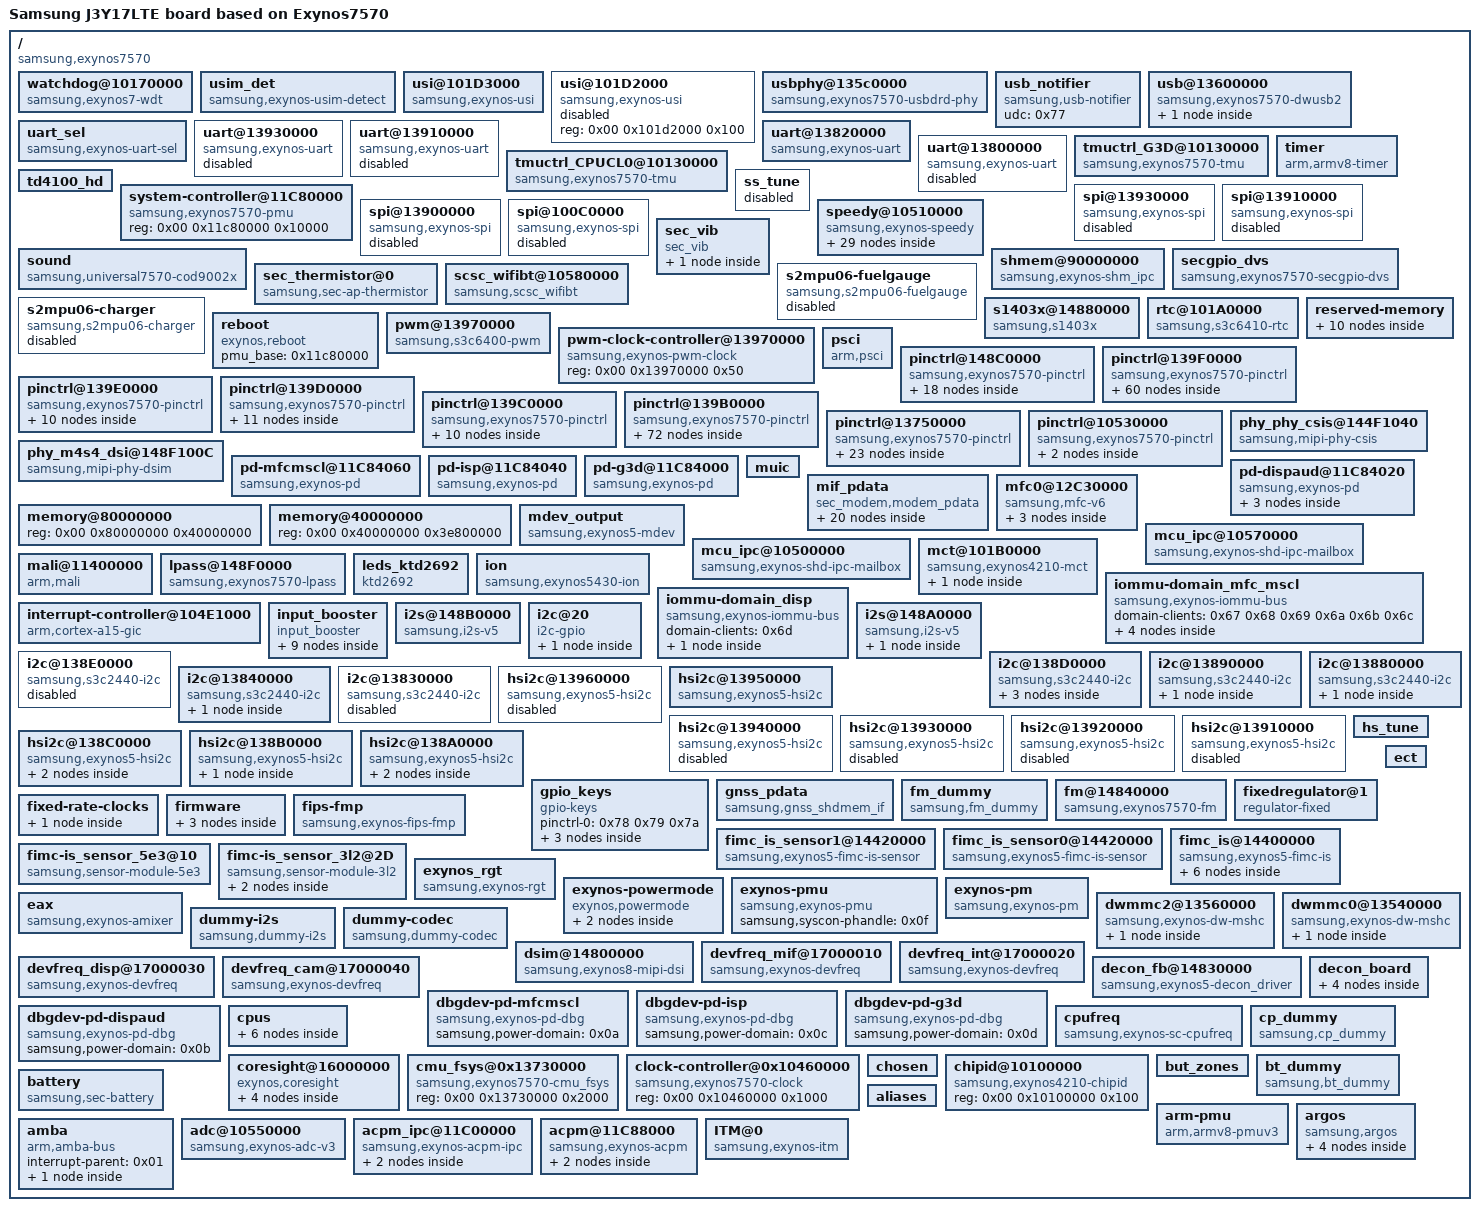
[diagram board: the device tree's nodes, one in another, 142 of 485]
/dts-v1/;

/ {
	#address-cells = <0x02>;
	#size-cells = <0x01>;
	compatible = "samsung,exynos7570\0samsung,exynos4210";
	interrupt-parent = <0x01>;
	model = "Samsung J3Y17LTE board based on Exynos7570";
	model_info-chip = <0x1d92>;
	model_info-hw_rev = <0x04>;
	model_info-hw_rev_end = <0xff>;
	model_info-platform = "android";
	model_info-subtype = "samsung";
	model_info-system_rev = "004";

	watchdog@10170000 {
		reg = <0x00 0x10170000 0x100>;
		interrupts = <0x00 0x64 0x00>;
		compatible = "samsung,exynos7-wdt";
		clock-names = "rate_watchdog\0gate_watchdog";
		timeout-sec = <0x1e>;
		clocks = <0x11 0x173 0x11 0x173>;
		samsung,syscon-phandle = <0x0f>;
	};

	usim_det {
		mif,usim-det0-gpio = <0x17 0x04 0x00>;
		pinctrl-0 = <0x15 0x16>;
		mif,usim-det1-gpio = <0x18 0x04 0x00>;
		compatible = "samsung,exynos-usim-detect";
		mif,int_usim1_det_level = <0x05>;
		mbx_ap2cp_united_status = <0x02>;
		sbi_usim1_det_pos = <0x12>;
		mif,int_usim0_det_level = <0x04>;
		sbi_usim0_det_mask = <0x01>;
		mif,num_of_usim_det = <0x02>;
		sbi_usim0_det_pos = <0x11>;
		sbi_usim1_det_mask = <0x01>;
		pinctrl-names = "default";
	};

	usi@101D3000 {
		reg = <0x00 0x101d3000 0x100>;
		compatible = "samsung,exynos-usi";
		status = "okay";
		usi_mode = "hsi2c1";
	};

	usi@101D2000 {
		reg = <0x00 0x101d2000 0x100>;
		compatible = "samsung,exynos-usi";
		status = "disabled";
	};

	usbphy@135c0000 {
		reg = <0x00 0x135c0000 0x100>;
		compatible = "samsung,exynos7570-usbdrd-phy";
		clock-names = "usbdrd20\0phyumux\0usb_pll";
		#phy-cells = <0x01>;
		use_additional_tuning;
		request_extrefclk;
		clocks = <0x11 0x200 0x11 0x208 0x11 0x212>;
		uart_io_share_mask = <0x01>;
		is_not_vbus_pad;
		ss_tune_info = <0x70>;
		status = "okay";
		samsung,pmu-syscon = <0x0f>;
		uart_io_share_enable = <0x01>;
		phandle = <0x6e>;
		uart_io_share_offset = <0x6200>;
		linux,phandle = <0x6e>;
		hs_tune_info = <0x6f>;
	};

	usb_notifier {
		udc = <0x77>;
		compatible = "samsung,usb-notifier";
	};

	usb@13600000 {
		reg = <0x00 0x13600000 0x10000>;
		compatible = "samsung,exynos7570-dwusb2";
		clock-names = "usbdrd20";
		clocks = <0x11 0x200>;
		ranges;
		status = "okay";
		#address-cells = <0x02>;
		phandle = <0x77>;
		#size-cells = <0x01>;
		linux,phandle = <0x77>;

		dwc3 {
			reg = <0x00 0x13600000 0x10000>;
			maximum-speed = "high-speed";
			phys = <0x6e 0x00 0x6e 0x01>;
			interrupts = <0x00 0xe6 0x00>;
			enable_sprs_transfer;
			compatible = "synopsys,dwc3";
			dr_mode = "otg";
			phy-names = "usb2-phy\0usb3-phy";
			is_not_vbus_pad;
			suspend_clk_freq = <0x3fe56c0>;
		};
	};

	uart_sel {
		int_ap2cp_uart_noti = <0x0f>;
		compatible = "samsung,exynos-uart-sel";
		mbx_ap2cp_united_status = <0x02>;
		sbi_uart_noti_pos = <0x10>;
		sbi_uart_noti_mask = <0x01>;
	};

	uart@13930000 {
		reg = <0x00 0x13930000 0x100>;
		interrupts = <0x00 0x1d1 0x00>;
		pinctrl-0 = <0x1a>;
		compatible = "samsung,exynos-uart";
		clock-names = "gate_pclk4\0gate_uart4\0sclk_uart4";
		clocks = <0x11 0x160 0x11 0x29 0x11 0x29>;
		samsung,fifo-size = <0x20>;
		samsung,separate-uart-clk;
		status = "disabled";
		pinctrl-names = "default";
	};

	uart@13910000 {
		reg = <0x00 0x13910000 0x100>;
		interrupts = <0x00 0x1cd 0x00>;
		pinctrl-0 = <0x19>;
		compatible = "samsung,exynos-uart";
		clock-names = "gate_pclk3\0gate_uart3\0sclk_uart3";
		clocks = <0x11 0x15f 0x11 0x28 0x11 0x28>;
		samsung,fifo-size = <0x20>;
		samsung,separate-uart-clk;
		status = "disabled";
		pinctrl-names = "default";
	};

	uart@13820000 {
		reg = <0x00 0x13820000 0x100>;
		interrupts = <0x00 0x1a7 0x00>;
		pinctrl-0 = <0x13>;
		pinctrl-1 = <0x14>;
		compatible = "samsung,exynos-uart";
		clock-names = "gate_pclk2\0gate_uart2\0sclk_uart2";
		clocks = <0x11 0x168 0x11 0x14 0x11 0x14>;
		samsung,fifo-size = <0x100>;
		samsung,separate-uart-clk;
		status = "okay";
		samsung,alive-io;
		pinctrl-names = "default\0uart_sleep";
	};

	uart@13800000 {
		reg = <0x00 0x13800000 0x100>;
		interrupts = <0x00 0x1a5 0x00>;
		pinctrl-0 = <0x12>;
		compatible = "samsung,exynos-uart";
		clock-names = "gate_pclk1\0gate_uart1\0sclk_uart1";
		clocks = <0x11 0x169 0x11 0x15 0x11 0x15>;
		samsung,fifo-size = <0x10>;
		samsung,separate-uart-clk;
		status = "disabled";
		pinctrl-names = "default";
	};

	tmuctrl_G3D@10130000 {
		reg = <0x00 0x10130000 0x200>;
		interrupts = <0x00 0x1b3 0x00>;
		compatible = "samsung,exynos7570-tmu";
		gpu_idx_num = <0x05>;
		default_ptat_cont = <0x01>;
		gpu_cooling_table = <0x00 0x00 0xcaa30 0x00 0x01 0xa2990 0x00 0x02 0x87028 0x00 0x03 0x65518 0x00 0x04 0xfffffffe>;
	};

	tmuctrl_CPUCL0@10130000 {
		reg = <0x00 0x10130000 0x200>;
		interrupts = <0x00 0x1b3 0x00>;
		compatible = "samsung,exynos7570-tmu";
		default_ptat_cont = <0x01>;
	};

	timer {
		interrupts = <0x01 0x0d 0xff01 0x01 0x0e 0xff01 0x01 0x0b 0xff01 0x01 0x0a 0xff01>;
		compatible = "arm,armv8-timer";
		clock-frequency = <0x18cba80>;
		use-clocksource-only;
	};

	td4100_hd {
		rev = <0x02>;
		resolution = <0x2d0 0x500>;
		mode = <0x00>;
		size = <0x3e 0x6e>;
		timing,pms = <0x02 0x70 0x01>;
		timing,refresh = <0x3c>;
		timing,dsi-escape-clk = <0x10>;
		timing,decon_h-porch = <0x50 0x2f1 0x01>;
		timing,decon_v-porch = <0x0a 0x0a 0x01>;
		timing,dsim_h-porch = <0x50 0x2ee 0x01>;
		timing,dsim_v-porch = <0x0a 0x0a 0x01>;
		dispif_resol = <0x2d0 0x500>;
		panel_name = "td4100";
		timing,dsi-hs-clk = <0x2d8>;
		phandle = <0x64>;
		linux,phandle = <0x64>;
	};

	system-controller@11C80000 {
		reg = <0x00 0x11c80000 0x10000>;
		compatible = "samsung,exynos7570-pmu\0syscon";
		phandle = <0x0f>;
		linux,phandle = <0x0f>;
	};

	ss_tune {
		enable_ssc = <0x01 0x01>;
		los_mask_val = <0x104 0x104>;
		ssc_range = <0x00 0x01>;
		tx_swing_low = <0x7f 0x7f>;
		tx_deemphasis_3p5db = <0x18 0x18>;
		tx_swing_full = <0x7f 0x7f>;
		fix_rxeq_value = <0x04 0x04>;
		tx_boost_level = <0x04 0x04>;
		status = "disabled";
		tx_swing_level = <0x01 0x01>;
		set_crport_mpll_charge_pump = <0x00 0x00>;
		tx_deemphasis_6db = <0x18 0x18>;
		phandle = <0x70>;
		enable_fixed_rxeq_mode = <0x00 0x00>;
		set_crport_level_en = <0x00 0x00>;
		los_bias = <0x05 0x05>;
		tx_deemphasis_mode = <0x01 0x01>;
		linux,phandle = <0x70>;
	};

	spi@13930000 {
		reg = <0x00 0x13930000 0x100>;
		interrupts = <0x00 0x1d2 0x00>;
		pinctrl-0 = <0x4d>;
		compatible = "samsung,exynos-spi";
		clock-names = "spi\0spi_busclk0";
		clocks = <0x11 0x160 0x11 0x29>;
		swap-mode;
		samsung,spi-fifosize = <0x20>;
		status = "disabled";
		#address-cells = <0x01>;
		#size-cells = <0x00>;
		dma-names = "tx\0rx";
		pinctrl-names = "default";
	};

	spi@13910000 {
		reg = <0x00 0x13910000 0x100>;
		interrupts = <0x00 0x1ce 0x00>;
		pinctrl-0 = <0x4c>;
		compatible = "samsung,exynos-spi";
		clock-names = "spi\0spi_busclk0";
		clocks = <0x11 0x15f 0x11 0x28>;
		swap-mode;
		samsung,spi-fifosize = <0x20>;
		status = "disabled";
		#address-cells = <0x01>;
		#size-cells = <0x00>;
		dma-names = "tx\0rx";
		pinctrl-names = "default";
	};

	spi@13900000 {
		reg = <0x00 0x13900000 0x100>;
		interrupts = <0x00 0x1b1 0x00>;
		pinctrl-0 = <0x4b>;
		compatible = "samsung,exynos-spi";
		clock-names = "spi\0spi_busclk0";
		clocks = <0x11 0x16b 0x11 0x16>;
		swap-mode;
		samsung,spi-fifosize = <0x40>;
		status = "disabled";
		#address-cells = <0x01>;
		#size-cells = <0x00>;
		dma-names = "tx\0rx";
		pinctrl-names = "default";
	};

	spi@100C0000 {
		reg = <0x00 0x100c0000 0x100>;
		interrupts = <0x00 0x1b2 0x00>;
		pinctrl-0 = <0x4a>;
		compatible = "samsung,exynos-spi";
		clock-names = "spi\0spi_busclk0";
		clocks = <0x11 0x16a 0x11 0x17>;
		swap-mode;
		samsung,spi-fifosize = <0x100>;
		status = "disabled";
		#address-cells = <0x01>;
		#size-cells = <0x00>;
		dma-names = "tx\0rx";
		pinctrl-names = "default";
	};

	speedy@10510000 {
		reg = <0x00 0x10510000 0x2000>;
		samsung,always-interrupt-high;
		interrupts = <0x00 0x174 0x00>;
		pinctrl-0 = <0x43>;
		compatible = "samsung,exynos-speedy";
		clock-names = "gate_speedy";
		clocks = <0x11 0x0b>;
		status = "okay";
		#address-cells = <0x01>;
		#size-cells = <0x00>;
		pinctrl-names = "default";

		cod9002x@03 {
			reg = <0x03>;
			i2c-speedy-address;
			mic-bias2-voltage = <0x01>;
			compatible = "codec,cod9002x";
			but-zones-list = <0x46 0xe2 0x00 0xd9 0x46 0x246 0xda 0x128 0x46 0x73 0x129 0x1f2 0x46 0x72 0x1f3 0x3e8>;
			io-channel-names = "adc-jack";
			use-jack-pullup-mode;
			io-channel-ranges;
			mic-bias1-voltage = <0x01>;
			use-btn-adc-mode;
			io-channels = <0x45 0x02>;
			mic-adc-range = <0x546>;
			phandle = <0x49>;
			vdd-supply = <0x44>;
			mic-bias-ldo-voltage = <0x03>;
			btn-press-delay = <0x00>;
			#io-channel-cells = <0x01>;
			pinctrl-names = "default";
			linux,phandle = <0x49>;
		};

		s2mpu06mfd@00 {
			reg = <0x00>;
			samsung,codec-interrupt = <0x49>;
			wtsr_en = "enabled";
			i2c-speedy-address;
			pinctrl-0 = <0x47>;
			cache_data = <0x01>;
			s2mpu06,irq-gpio = <0x48 0x05 0x00>;
			check_jigon = <0x00>;
			compatible = "samsung,s2mpu06mfd";
			smpl_timer_val = <0x00>;
			smpl_en = "enabled";
			wtsr_timer_val = <0x03>;
			s2mpu06,wakeup = "enabled";
			init_time,hour = <0x0c>;
			init_time,mday = <0x01>;
			init_time,wday = <0x00>;
			init_time,year = <0x75>;
			pinctrl-names = "default";
			init_time,min = <0x00>;
			init_time,mon = <0x00>;
			init_time,sec = <0x00>;

			s2mpu06-keys {

				button@1 {
					label = "pmic-keys: KEY_POWER";
					linux,code = <0x74>;
					wakeup = <0x01>;
				};
			};

			regulators {

				LDO24 {
					regulator-name = "AVDD24_CAM_2P8";
					regulator-min-microvolt = <0x2ab980>;
					regulator-max-microvolt = <0x2ab980>;
					regulator-initial-mode = <0x00>;
					regulator-ramp-delay = <0x2ee0>;
				};

				LDO23 {
					regulator-name = "VDD23_CAM_CORE_1P2";
					regulator-min-microvolt = <0x124f80>;
					regulator-max-microvolt = <0x124f80>;
					regulator-initial-mode = <0x00>;
					regulator-ramp-delay = <0x2ee0>;
				};

				LDO22 {
					regulator-name = "vdd_ldo22";
					regulator-always-on;
					regulator-min-microvolt = <0x1b7740>;
					regulator-max-microvolt = <0x337f98>;
					regulator-initial-mode = <0x03>;
					phandle = <0x28>;
					regulator-ramp-delay = <0x2ee0>;
					linux,phandle = <0x28>;
				};

				LDO21 {
					regulator-name = "vdd_ldo21";
					regulator-min-microvolt = <0x1b7740>;
					regulator-max-microvolt = <0x337f98>;
					regulator-initial-mode = <0x00>;
					regulator-ramp-delay = <0x2ee0>;
				};

				LDO20 {
					regulator-name = "LCD_1P8";
					regulator-min-microvolt = <0x1b7740>;
					regulator-max-microvolt = <0x1b7740>;
					regulator-initial-mode = <0x03>;
					regulator-boot-on;
				};

				LDO19 {
					regulator-name = "vtouch_2.2v";
					regulator-min-microvolt = <0x2191c0>;
					regulator-max-microvolt = <0x2191c0>;
					regulator-boot-on;
				};

				LDO18 {
					regulator-name = "VDD28_CAM_AF";
					regulator-min-microvolt = <0x2ab980>;
					regulator-max-microvolt = <0x2ab980>;
					regulator-initial-mode = <0x00>;
					regulator-ramp-delay = <0x2ee0>;
				};

				LDO17 {
					regulator-name = "VDD18_CAM_SENSOR_IO";
					regulator-min-microvolt = <0x1b7740>;
					regulator-max-microvolt = <0x1b7740>;
					regulator-initial-mode = <0x00>;
					regulator-ramp-delay = <0x2ee0>;
				};

				LDO16 {
					regulator-name = "VDD_MOTOR_3P3";
					regulator-min-microvolt = <0x325aa0>;
					regulator-max-microvolt = <0x325aa0>;
					regulator-initial-mode = <0x00>;
					regulator-ramp-delay = <0x2ee0>;
				};

				LDO15 {
					regulator-name = "vqemmc";
					regulator-min-microvolt = "\0\f5";
					regulator-max-microvolt = <0x1e8480>;
					regulator-initial-mode = <0x00>;
					regulator-ramp-delay = <0x2ee0>;
				};

				LDO14 {
					regulator-name = "vemmc";
					regulator-min-microvolt = <0x1b7740>;
					regulator-max-microvolt = <0x337f98>;
					regulator-initial-mode = <0x00>;
					regulator-ramp-delay = <0x2ee0>;
				};

				LDO13 {
					regulator-name = "vdd_ldo13";
					regulator-always-on;
					regulator-min-microvolt = "\0\f5";
					regulator-max-microvolt = <0x1e8480>;
					regulator-initial-mode = <0x03>;
					phandle = <0x44>;
					regulator-boot-on;
					regulator-ramp-delay = <0x2ee0>;
					linux,phandle = <0x44>;
				};

				BUCK3 {
					regulator-name = "BUCK3";
					regulator-always-on;
					regulator-min-microvolt = "\0\f5";
					regulator-max-microvolt = <0x2ab980>;
					regulator-initial-mode = <0x03>;
					regulator-boot-on;
					regulator-ramp-delay = <0x2ee0>;
				};

				BUCK2 {
					regulator-name = "BUCK2";
					regulator-always-on;
					regulator-min-microvolt = "\0\f5";
					regulator-max-microvolt = <0x2ab980>;
					regulator-initial-mode = <0x03>;
					regulator-boot-on;
					regulator-ramp-delay = <0x2ee0>;
				};

				BUCK1 {
					regulator-expected-consumer = <0x06>;
					regulator-name = "BUCK1";
					regulator-always-on;
					regulator-min-microvolt = <0x7a120>;
					regulator-max-microvolt = <0x13d620>;
					regulator-initial-mode = <0x01>;
					regulator-boot-on;
					regulator-ramp-delay = <0x2ee0>;
				};

				LDO8 {
					regulator-name = "vdd_ldo8";
					regulator-always-on;
					regulator-min-microvolt = <0x1b7740>;
					regulator-max-microvolt = <0x337f98>;
					regulator-initial-mode = <0x01>;
					regulator-boot-on;
					regulator-ramp-delay = <0x2ee0>;
				};

				LDO7 {
					regulator-name = "vdd_ldo7";
					regulator-always-on;
					regulator-min-microvolt = "\0\f5";
					regulator-max-microvolt = <0x13d620>;
					regulator-initial-mode = <0x01>;
					regulator-boot-on;
					regulator-ramp-delay = <0x2ee0>;
				};

				LDO6 {
					regulator-name = "vdd_ldo6";
					regulator-always-on;
					regulator-min-microvolt = <0x7a120>;
					regulator-max-microvolt = <0x13d620>;
					regulator-initial-mode = <0x03>;
					regulator-boot-on;
					regulator-ramp-delay = <0x2ee0>;
				};

				LDO5 {
					regulator-name = "vdd_ldo5";
					regulator-always-on;
					regulator-min-microvolt = <0x19f0a0>;
					regulator-max-microvolt = <0x331df0>;
					regulator-initial-mode = <0x03>;
					regulator-boot-on;
					regulator-ramp-delay = <0x2ee0>;
				};

				LDO4 {
					regulator-name = "vqmmc";
					regulator-min-microvolt = <0x19f0a0>;
					regulator-max-microvolt = <0x331df0>;
					regulator-initial-mode = <0x00>;
					regulator-ramp-delay = <0x2ee0>;
				};

				LDO3 {
					regulator-name = "vdd_ldo3";
					regulator-always-on;
					regulator-min-microvolt = "\0\f5";
					regulator-max-microvolt = <0x16e360>;
					regulator-initial-mode = <0x03>;
					regulator-boot-on;
					regulator-ramp-delay = <0x2ee0>;
				};

				LDO2 {
					regulator-name = "vdd_ldo2";
					regulator-always-on;
					regulator-min-microvolt = <0x16e360>;
					regulator-max-microvolt = <0x1e8480>;
					regulator-initial-mode = <0x03>;
					phandle = <0x26>;
					regulator-boot-on;
					regulator-ramp-delay = <0x2ee0>;
					linux,phandle = <0x26>;
				};

				LDO1 {
					regulator-name = "vdd_ldo1";
					regulator-always-on;
					regulator-min-microvolt = <0x7a120>;
					regulator-max-microvolt = <0x13d620>;
					regulator-initial-mode = <0x01>;
					regulator-boot-on;
					regulator-ramp-delay = <0x2ee0>;
				};
			};
		};

		fimc_is_flash@06 {
			id = <0x00>;
			reg = <0x06>;
			i2c-speedy-address;
			torch_level1 = <0x00>;
			torch_level2 = <0x01>;
			torch_level3 = <0x02>;
			torch_level4 = <0x03>;
			torch_level5 = <0x06>;
			compatible = "samsung,sensor-flash-i2c";
			flash-gpio = <0x48 0x00 0x00>;
			flash_current = <0x4b0>;
			factory_current = <0xa0>;
			torch_current = <0x50>;
			movie_current = <0xa0>;
			preflash_current = <0xa0>;
		};
	};

	sound {
		compatible = "samsung,universal7570-cod9002x";
		status = "okay";
		samsung,audio-cpu = <0x84 0x84 0x85 0x86 0x87 0x88 0x85 0x89 0x89 0x89 0x89>;
		samsung,audio-codec = <0x49 0x49 0x49 0x8a 0x49 0x8a 0x8a 0x49 0x49 0x49 0x49>;
		mic-bias-mode = <0x01 0x01 0x02 0x00>;
		samsung,auxdev = <0x8b>;
	};

	shmem@90000000 {
		compatible = "samsung,exynos-shm_ipc";
		shmem,ipc_size = <0x400000>;
		shmem,ipc_offset = <0x5800000>;
	};

	secgpio_dvs {
		compatible = "samsung,exynos7570-secgpio-dvs";
		status = "okay";
	};

	sec_vib {
		compatible = "sec_vib";

		sec_vib_pdata {
			sec_vib,regulator = "VDD_MOTOR_3P3";
			sec_vib,max_timeout = <0x2710>;
			status = "okay";
			sec_vib,ldo_type = <0x00>;
		};
	};

	sec_thermistor@0 {
		compatible = "samsung,sec-ap-thermistor";
		io-channel-names = "adc-ap-temp";
		io-channel-ranges;
		status = "okay";
		io-channels = <0x45 0x00>;
		temp_array = <0x384 0x37a 0x370 0x366 0x35c 0x352 0x348 0x33e 0x334 0x32a 0x320 0x316 0x30c 0x302 0x2f8 0x2ee 0x2e4 0x2da 0x2d0 0x2c6 0x2bc 0x2b2 0x2a8 0x29e 0x294 0x28a 0x280 0x276 0x26c 0x262 0x258 0x24e 0x244 0x23a 0x230 0x226 0x21c 0x212 0x208 0x1fe 0x1f4 0x1ea 0x1e0 0x1d6 0x1cc 0x1c2 0x1b8 0x1ae 0x1a4 0x19a 0x190 0x186 0x17c 0x172 0x168 0x15e 0x154 0x14a 0x140 0x136 0x12c 0x122 0x118 0x10e 0x104 0xfa 0xf0 0xe6 0xdc 0xd2 0xc8 0xbe 0xb4 0xaa 0xa0 0x96 0x8c 0x82 0x78 0x6e 0x64 0x5a 0x50 0x46 0x3c 0x32 0x28 0x1e 0x14 0x0a 0x00 0xfffffff6 0xffffffec 0xffffffe2 0xffffffd8 0xffffffce 0xffffffc4 0xffffffba 0xffffffb0 0xffffffa6 0xffffff9c 0xffffff92 0xffffff88 0xffffff7e 0xffffff74 0xffffff6a 0xffffff60 0xffffff56 0xffffff4c 0xffffff42 0xffffff38>;
		adc_array = <0x11d 0x128 0x132 0x13d 0x147 0x152 0x15e 0x169 0x175 0x180 0x18c 0x198 0x1a4 0x1b1 0x1bd 0x1c9 0x1da 0x1eb 0x1fc 0x20d 0x21d 0x233 0x248 0x25d 0x272 0x288 0x29c 0x2b2 0x2c7 0x2dc 0x2f1 0x308 0x31e 0x336 0x34c 0x364 0x382 0x3a0 0x3be 0x3dc 0x3fa 0x41b 0x43c 0x45d 0x47e 0x49f 0x4c1 0x4e3 0x506 0x528 0x54a 0x573 0x59b 0x5c4 0x5ec 0x615 0x643 0x671 0x6a0 0x6cf 0x6fd 0x727 0x752 0x77d 0x7a7 0x7d1 0x801 0x831 0x861 0x892 0x8c2 0x8f3 0x924 0x955 0x985 0x9b5 0x9e3 0xa10 0xa3e 0xa6b 0xa99 0xac3 0xaed 0xb16 0xb40 0xb6a 0xb95 0xbbf 0xbea 0xc14 0xc3f 0xc60 0xc81 0xca3 0xcc4 0xce5 0xd02 0xd20 0xd3d 0xd5b 0xd78 0xd8e 0xda4 0xdba 0xdd0 0xde6 0xdfe 0xe17 0xe2f 0xe48 0xe60>;
	};

	scsc_wifibt@10580000 {
		reg = <0x00 0x10580000 0x180>;
		interrupts = <0x00 0x178 0x04 0x00 0x15 0x04 0x00 0x1dc 0x04>;
		compatible = "samsung,scsc_wifibt";
		interrupt-names = "MBOX\0ALIVE\0WDOG";
		samsung,syscon-cmu_fsys = <0x66>;
		usbpll,udelay = <0x14>;
		status = "okay";
		samsung,syscon-phandle = <0x0f>;
		usbpll,owner = "y";
	};

	s2mpu06-fuelgauge {
		fuelgauge,capacity_full = <0x960>;
		fuelgauge,fuel_alert_soc = <0x01>;
		fuelgauge,model_type = <0x01>;
		fuelgauge,capacity_max = <0x3e8>;
		fuelgauge,capacity_min = <0x00>;
		compatible = "samsung,s2mpu06-fuelgauge";
		fuelgauge,capacity_max_margin = <0x46>;
		fuelgauge,raw_100_vbat = <0x10d1 0x10cc 0x10b9 0x10a5 0x1077>;
		status = "disable";
		fuelgauge,capacity_calculation_type = <0x1c>;
		fuelgauge,cell_character = <0xb8 0x0a 0x71 0x0a 0xe2 0x09 0x74 0x09 0x21 0x09 0x83 0x08 0x25 0x08 0xd6 0x07 0x8d 0x07 0x3e 0x07 0xe0 0x06 0xaa 0x06 0x82 0x06 0x63 0x06 0x4a 0x06 0x33 0x06 0x0f 0x06 0xe8 0x05 0xaf 0x05 0x85 0x05 0x22 0x05 0x35 0x02 0x69 0x08 0x00 0x08 0x97 0x07 0x2e 0x07 0xc5 0x06 0x5c 0x06 0xf3 0x05 0x8b 0x05 0x22 0x05 0xb9 0x04 0x50 0x04 0xe7 0x03 0x7e 0x03 0x15 0x03 0xac 0x02 0x43 0x02 0xda 0x01 0x72 0x01 0x09 0x01 0xa0 0x00 0x37 0x00 0xe0 0x0f 0xfe 0x29 0xdc 0x29 0x8a 0x29 0x4d 0x29 0x28 0x1f 0x7f 0x1f 0x21 0x21 0x14 0x21 0xe8 0x0f 0xe6 0xf7 0xc4 0x1d 0xca 0xd4 0xd3 0xd4 0x40 0x80 0x26 0x33 0x26 0x40 0x26 0x5c 0x26 0x5c 0x26 0x5c 0xff 0xff 0x02 0x05 0x14 0x0b 0x03 0x12 0x06 0x1c 0x0c 0x1c 0x10 0x1c 0x1f 0x1f 0x30 0x30 0x38 0x38 0x38 0x38 0x38 0x38 0x3d 0x3d 0x3e 0x3f 0x3f 0x3f 0x40 0x4b 0x4b 0x4c 0x4e 0x4d 0x71 0xa4 0x05 0x60 0x09 0x00 0x00 0x66 0x0a 0xf5 0x09 0x8a 0x09 0x22 0x09 0xc1 0x08 0x6d 0x08 0x00 0x08 0xbe 0x07 0x67 0x07 0x05 0x07 0xc9 0x06 0x9d 0x06 0x79 0x06 0x5c 0x06 0x43 0x06 0x26 0x06 0x04 0x06 0xdc 0x05 0xa8 0x05 0x84 0x05 0xd6 0x04 0x7f 0x01 0x00 0x08 0xa0 0x07 0x3d 0x07 0xda 0x06 0x78 0x06 0x15 0x06 0xb2 0x05 0x4f 0x05 0xec 0x04 0x8a 0x04 0x27 0x04 0xc4 0x03 0x61 0x03 0xfe 0x02 0x9c 0x02 0x39 0x02 0xd6 0x01 0x73 0x01 0x10 0x01 0xae 0x00 0x4b 0x00 0xe8 0x0f 0xfe 0x29 0xdc 0x29 0x8a 0x29 0x4d 0x29 0x28 0x1f 0x7f 0x1f 0x21 0x21 0x14 0x21 0xf7 0x0f 0xe6 0xf7 0xc4 0x1d 0xca 0xd4 0xd3 0xd4 0x40 0x80 0x26 0x33 0x26 0x40 0x26 0x5c 0x26 0x5c 0x26 0x5c 0xff 0xff 0x02 0x05 0x14 0x0b 0x03 0x12 0x06 0x1c 0x0c 0x1c 0x10 0x1c 0x1f 0x1f 0x37 0x37 0x37 0x37 0x37 0x38 0x38 0x37 0x37 0x38 0x38 0x38 0x38 0x39 0x39 0x39 0x39 0x39 0x3a 0x3b 0x41 0xc8 0x05 0x60 0x09 0x00 0x00 0x40 0x0a 0xd2 0x09 0x69 0x09 0x04 0x09 0xa5 0x08 0x4f 0x08 0xee 0x07 0xab 0x07 0x53 0x07 0xf7 0x06 0xc0 0x06 0x96 0x06 0x74 0x06 0x59 0x06 0x41 0x06 0x23 0x06 0x01 0x06 0xda 0x05 0xa5 0x05 0x86 0x05 0xe4 0x04 0x7c 0x01 0x00 0x08 0xa1 0x07 0x3e 0x07 0xdb 0x06 0x78 0x06 0x15 0x06 0xb2 0x05 0x4f 0x05 0xed 0x04 0x8a 0x04 0x27 0x04 0xc4 0x03 0x61 0x03 0xfe 0x02 0x9c 0x02 0x39 0x02 0xd6 0x01 0x73 0x01 0x10 0x01 0xad 0x00 0x4b 0x00 0xe8 0x0f 0xfe 0x29 0xdc 0x29 0x8a 0x29 0x4d 0x29 0x28 0x1f 0x7f 0x1f 0x21 0x21 0x14 0x21 0xf7 0x0f 0xe6 0xf7 0xc4 0x1d 0xca 0xd4 0xd3 0xd4 0x40 0x80 0x26 0x33 0x26 0x40 0x26 0x5c 0x26 0x5c 0x26 0x5c 0xff 0xff 0x02 0x05 0x14 0x0b 0x03 0x12 0x06 0x1c 0x0c 0x1c 0x10 0x1c 0x1f 0x1f 0x36 0x36 0x36 0x37 0x36 0x38 0x38 0x37 0x37 0x37 0x38 0x38 0x38 0x38 0x39 0x39 0x38 0x39 0x3a 0x3b 0x40 0xcd 0x05 0x60 0x09 0x00 0x00 0x17 0x0a 0xa8 0x09 0x41 0x09 0xdf 0x08 0x8a 0x08 0x1d 0x08 0xdb 0x07 0x95 0x07 0x33 0x07 0xe3 0x06 0xb2 0x06 0x8b 0x06 0x6b 0x06 0x52 0x06 0x3d 0x06 0x1f 0x06 0xfc 0x05 0xd7 0x05 0xa0 0x05 0x85 0x05 0x0b 0x05 0x7e 0x01 0x00 0x08 0x9d 0x07 0x3a 0x07 0xd7 0x06 0x74 0x06 0x11 0x06 0xae 0x05 0x4b 0x05 0xe7 0x04 0x84 0x04 0x21 0x04 0xbe 0x03 0x5b 0x03 0xf8 0x02 0x95 0x02 0x32 0x02 0xcf 0x01 0x6c 0x01 0x09 0x01 0xa6 0x00 0x43 0x00 0xe5 0x0f 0xfe 0x29 0xdc 0x29 0x8a 0x29 0x4d 0x29 0x28 0x1f 0x7f 0x1f 0x21 0x21 0x14 0x21 0xf7 0x0f 0xe6 0xf7 0xc4 0x1d 0xca 0xd4 0xd3 0xd4 0x40 0x80 0x26 0x33 0x26 0x40 0x26 0x5c 0x26 0x5c 0x26 0x5c 0xff 0xff 0x02 0x05 0x14 0x0b 0x03 0x12 0x06 0x1c 0x0c 0x1c 0x10 0x1c 0x1f 0x1f 0x35 0x36 0x36 0x36 0x36 0x36 0x38 0x37 0x37 0x37 0x37 0x37 0x38 0x38 0x39 0x39 0x39 0x39 0x3a 0x3b 0x3f 0xd0 0x05 0x60 0x09 0x00 0x00 0xb7 0x09 0x4f 0x09 0xee 0x08 0x95 0x08 0x34 0x08 0xe8 0x07 0xa7 0x07 0x51 0x07 0xf4 0x06 0xbf 0x06 0x97 0x06 0x76 0x06 0x5b 0x06 0x45 0x06 0x2b 0x06 0x08 0x06 0xea 0x05 0xbb 0x05 0x89 0x05 0x7a 0x05 0x08 0x04 0x64 0x01 0x00 0x08 0x9b 0x07 0x36 0x07 0xd0 0x06 0x6b 0x06 0x06 0x06 0xa1 0x05 0x3c 0x05 0xd7 0x04 0x72 0x04 0x0c 0x04 0xa7 0x03 0x42 0x03 0xdd 0x02 0x78 0x02 0x13 0x02 0xae 0x01 0x49 0x01 0xe4 0x00 0x7e 0x00 0x19 0x00 0xe7 0x0f 0xfe 0x29 0xdc 0x29 0x8a 0x29 0x4d 0x29 0x28 0x1f 0x7f 0x1f 0x21 0x21 0x14 0x21 0xf7 0x0f 0xe6 0xf7 0xc4 0x1d 0xca 0xd4 0xd3 0xd4 0x40 0x80 0x26 0x33 0x26 0x40 0x26 0x5c 0x26 0x5c 0x26 0x5c 0xff 0xff 0x02 0x05 0x14 0x0b 0x03 0x12 0x06 0x1c 0x0c 0x1c 0x10 0x1c 0x1f 0x1f 0x35 0x36 0x36 0x37 0x37 0x39 0x38 0x38 0x37 0x38 0x38 0x38 0x38 0x39 0x38 0x38 0x38 0x39 0x39 0x3b 0x43 0xc1 0x05 0x60 0x09 0x00 0x00>;
		fuelgauge,type_str = "SDI";
	};

	s2mpu06-charger {
		battery,chg_gpio_status = <0x00>;
		compatible = "samsung,s2mpu06-charger";
		battery,chg_polarity_en = <0x00>;
		battery,chg_gpio_en = <0x00>;
		battery,chg_polarity_status = <0x00>;
		status = "disable";
		battery,is_1MHz_switching = <0x01>;
	};

	s1403x@14880000 {
		reg = <0x00 0x14880000 0x200>;
		pinctrl-0 = <0x3b 0x3c>;
		pinctrl-1 = <0x3d>;
		compatible = "samsung,s1403x";
		clock-names = "audmixer_dout\0audmixer_aclk";
		clocks = <0x11 0x2e6 0x11 0x2c6>;
		samsung,lpass-subip;
		status = "okay";
		phandle = <0x8b>;
		pinctrl-names = "default\0idle";
		linux,phandle = <0x8b>;
	};

	rtc@101A0000 {
		reg = <0x00 0x101a0000 0x100>;
		interrupts = <0x00 0x5c 0x00 0x00 0x5d 0x00>;
		compatible = "samsung,s3c6410-rtc";
		clock-names = "gate_rtc";
		clocks = <0x11 0x176>;
	};

	reserved-memory {
		ranges;
		#address-cells = <0x02>;
		#size-cells = <0x01>;

		wifibt_if {
			reg = <0x00 0x79000000 0x400000>;
			compatible = "exynos,wifibt_if";
		};

		tima_region@0x52800000 {
			reg = <0x00 0x52800000 0x200000>;
			compatible = "removed-dma-pool";
		};

		video_stream {
			id = <0x03>;
			reg = <0x00 0x72200000 0x1200000>;
			compatible = "exynos8890-ion,vstream";
			compat-id = <0x19 0x1f>;
			secure;
		};

		video_scaler {
			id = <0x06>;
			reg = <0x00 0x71200000 0x1000000>;
			reusable;
			compatible = "exynos8890-ion,vscaler";
			compat-id = <0x1c>;
			secure;
		};

		gnss_if {
			reg = <0x00 0x7e100000 0x200000>;
			compatible = "exynos,gnss_if";
		};

		video_frame {
			id = <0x05>;
			reg = <0x00 0x79c00000 0x3800000>;
			ion,bulk_reclaim;
			reusable;
			compatible = "exynos8890-ion,vframe";
			compat-id = <0x1a 0x1d>;
			secure;
		};

		crypto {
			id = <0x01>;
			reg = <0x00 0x79400000 0x800000>;
			reusable;
			compatible = "exynos8890-ion,crypto";
		};

		camera {
			id = <0x0a>;
			reg = <0x00 0x710ef000 0x1000>;
			compatible = "exynos8890-ion,camera";
		};

		modem_if {
			reg = <0x00 0x73400000 0x5c00000>;
			compatible = "exynos,modem_if";
		};

		video_nfw {
			reg = <0x00 0x710f0000 0x110000>;
			fixed_lower_base = <0x40000000>;
			compatible = "exynos7570-mfc,vnfw";
			fixed_upper_base = <0xffffff80>;
		};
	};

	reboot {
		pmu_base = <0x11c80000>;
		compatible = "exynos,reboot";
	};

	pwm@13970000 {
		reg = <0x00 0x13970000 0x1000>;
		samsung,pwm-outputs = <0x00 0x01 0x02 0x03 0x04>;
		compatible = "samsung,s3c6400-pwm";
		clock-names = "gate_timers\0sclk_pwm\0pwm-scaler0\0pwm-scaler1\0pwm-tdiv0\0pwm-tdiv1\0pwm-tdiv2\0pwm-tdiv3\0pwm-tin0\0pwm-tin1\0pwm-tin2\0pwm-tin3";
		clocks = <0x11 0x14a 0x11 0x14b 0x71 0x01 0x71 0x02 0x71 0x05 0x71 0x06 0x71 0x07 0x71 0x08 0x71 0x0a 0x71 0x0b 0x71 0x0c 0x71 0x0d>;
		#pwm-cells = <0x03>;
		samsung,pwm-sclk-ctrl;
		status = "ok";
	};

	pwm-clock-controller@13970000 {
		reg = <0x00 0x13970000 0x50>;
		#clock-cells = <0x01>;
		compatible = "samsung,exynos-pwm-clock";
		phandle = <0x71>;
		linux,phandle = <0x71>;
	};

	psci {
		cpu_off = <0x84000002>;
		compatible = "arm,psci";
		cpu_suspend = <0xc4000001>;
		cpu_on = <0xc4000003>;
		method = "smc";
	};

	pinctrl@148C0000 {
		reg = <0x00 0x148c0000 0x1000>;
		interrupts = <0x00 0x44 0x00>;
		pinctrl-0 = <0x04>;
		compatible = "samsung,exynos7570-pinctrl";
		pinctrl-names = "sleep";

		i2s-pmic-bus {
			samsung,pin-function = <0x02>;
			samsung,pins = "gpz1-0\0gpz1-1\0gpz1-2\0gpz1-3";
			samsung,pin-drv = <0x00>;
			samsung,pin-pud = <0x01>;
		};

		fm-speedy-bus-idle {
			samsung,pin-function = <0x00>;
			samsung,pins = "gpz1-6";
			samsung,pin-drv = <0x02>;
			samsung,pin-pud = <0x03>;
		};

		i2s-amp-bus-idle {
			samsung,pin-function = <0x00>;
			samsung,pins = "gpz1-5";
			samsung,pin-drv = <0x02>;
			samsung,pin-pud = <0x03>;
		};

		i2s-pmic-amp-bus-idle {
			samsung,pin-function = <0x00>;
			samsung,pins = "gpz1-0\0gpz1-1\0gpz1-2\0gpz1-3\0gpz1-4\0gpz1-5";
			samsung,pin-drv = <0x00>;
			samsung,pin-pud = <0x01>;
			phandle = <0x3d>;
			linux,phandle = <0x3d>;
		};

		i2s-codec-clk {
			samsung,pin-function = <0x02>;
			samsung,pins = "gpz1-4";
			samsung,pin-drv = <0x00>;
			samsung,pin-pud = <0x01>;
			phandle = <0x3c>;
			linux,phandle = <0x3c>;
		};

		fm-speedy-bus {
			samsung,pin-function = <0x02>;
			samsung,pins = "gpz1-6";
			samsung,pin-drv = <0x02>;
			samsung,pin-pud = <0x03>;
		};

		i2s-pmic-amp-bus {
			samsung,pin-function = <0x02>;
			samsung,pins = "gpz1-0\0gpz1-1\0gpz1-2\0gpz1-3\0gpz1-4\0gpz1-5";
			samsung,pin-drv = <0x00>;
			samsung,pin-pud = <0x01>;
			phandle = <0x3b>;
			linux,phandle = <0x3b>;
		};

		i2s-pmic-bus-idle {
			samsung,pin-function = <0x00>;
			samsung,pins = "gpz1-0\0gpz1-1\0gpz1-2\0gpz1-3";
			samsung,pin-drv = <0x00>;
			samsung,pin-pud = <0x01>;
		};

		sleep-state {
			phandle = <0x04>;
			linux,phandle = <0x04>;

			gpz1-6 {
				samsung,pin-pud-pdn = <0x01>;
				samsung,pin-con-pdn = <0x02>;
				samsung,pins = "gpz1-6";
			};

			gpz1-5 {
				samsung,pin-pud-pdn = <0x01>;
				samsung,pin-con-pdn = <0x02>;
				samsung,pins = "gpz1-5";
			};

			gpz1-4 {
				samsung,pin-pud-pdn = <0x01>;
				samsung,pin-con-pdn = <0x02>;
				samsung,pins = "gpz1-4";
			};

			gpz1-3 {
				samsung,pin-pud-pdn = <0x01>;
				samsung,pin-con-pdn = <0x02>;
				samsung,pins = "gpz1-3";
			};

			gpz1-2 {
				samsung,pin-pud-pdn = <0x01>;
				samsung,pin-con-pdn = <0x02>;
				samsung,pins = "gpz1-2";
			};

			gpz1-1 {
				samsung,pin-pud-pdn = <0x01>;
				samsung,pin-con-pdn = <0x02>;
				samsung,pins = "gpz1-1";
			};

			gpz1-0 {
				samsung,pin-pud-pdn = <0x01>;
				samsung,pin-con-pdn = <0x02>;
				samsung,pins = "gpz1-0";
			};
		};

		i2s-amp-bus {
			samsung,pin-function = <0x02>;
			samsung,pins = "gpz1-5";
			samsung,pin-drv = <0x02>;
			samsung,pin-pud = <0x03>;
		};

		gpz1 {
			#gpio-cells = <0x02>;
			#interrupt-cells = <0x02>;
			interrupt-controller;
			gpio-controller;
		};
	};

	pinctrl@139F0000 {
		reg = <0x00 0x139f0000 0x1000>;
		interrupts = <0x00 0x00 0x00 0x00 0x01 0x00 0x00 0x02 0x00 0x00 0x03 0x00 0x00 0x04 0x00 0x00 0x05 0x00 0x00 0x06 0x00 0x00 0x07 0x00 0x00 0x08 0x00 0x00 0x09 0x00 0x00 0x0a 0x00 0x00 0x0b 0x00 0x00 0x0c 0x00 0x00 0x0d 0x00 0x00 0x0e 0x00 0x00 0x0f 0x00>;
		pinctrl-0 = <0x02>;
		compatible = "samsung,exynos7570-pinctrl";
		pinctrl-names = "default";

		key-voldown {
			samsung,pin-function = <0x0f>;
			samsung,pins = "gpa2-3";
			samsung,pin-drv = <0x00>;
			samsung,pin-pud = <0x03>;
			phandle = <0x78>;
			linux,phandle = <0x78>;
		};

		uart4-bus-single {
			samsung,pin-function = <0x02>;
			samsung,pins = "gpa2-5\0gpa2-4\0gpa2-6\0gpa2-7";
			samsung,pin-pud = <0x00>;
			phandle = <0x1a>;
			linux,phandle = <0x1a>;
		};

		i2c6-bus {
			samsung,pin-function = <0x02>;
			samsung,pins = "gpa1-6\0gpa1-5";
			samsung,pin-drv = <0x00>;
			samsung,pin-pud = <0x03>;
			phandle = <0x29>;
			linux,phandle = <0x29>;
		};

		cp_gpio_j3pop_old {
			samsung,pin-function = <0x04>;
			samsung,pins = "gpa1-3";
			samsung,pin-pud = <0x00>;
		};

		uart3-bus-dual {
			samsung,pin-function = <0x02>;
			samsung,pins = "gpa2-0\0gpa1-7";
			samsung,pin-pud = <0x00>;
		};

		initial-state {
			phandle = <0x02>;
			linux,phandle = <0x02>;

			gpa2-5 {
				samsung,pin-function = <0x00>;
				samsung,pins = "gpa2-5";
				samsung,pin-drv = <0x00>;
				samsung,pin-pud = <0x00>;
			};

			gpa1-3 {
				samsung,pin-function = <0x00>;
				samsung,pins = "gpa1-3";
				samsung,pin-drv = <0x00>;
				samsung,pin-pud = <0x01>;
			};
		};

		sim_gpio_default_on5 {
			samsung,pin-function = <0x00>;
			samsung,pins = "gpa2-4";
			samsung,pin-pud = <0x00>;
		};

		sim1_gpio_on5 {
			samsung,pin-function = <0x0f>;
			samsung,pins = "gpa1-4";
			samsung,pin-pud = <0x00>;
			phandle = <0x16>;
			linux,phandle = <0x16>;
		};

		uart2-bus {
			samsung,pin-function = <0x03>;
			samsung,pins = "gpa1-6\0gpa1-5";
			samsung,pin-pud = <0x00>;
			phandle = <0x13>;
			linux,phandle = <0x13>;
		};

		key-home {
			samsung,pin-function = <0x0f>;
			samsung,pins = "gpa0-4";
			samsung,pin-drv = <0x00>;
			samsung,pin-pud = <0x03>;
			phandle = <0x7a>;
			linux,phandle = <0x7a>;
		};

		uart3-bus-single {
			samsung,pin-function = <0x02>;
			samsung,pins = "gpa2-0\0gpa1-7\0gpa2-1\0gpa2-2";
			samsung,pin-pud = <0x00>;
			phandle = <0x19>;
			linux,phandle = <0x19>;
		};

		prox_int {
			samsung,pin-function = <0x00>;
			samsung,pins = "gpa1-0";
			samsung,pin-drv = <0x00>;
			samsung,pin-pud = <0x00>;
			phandle = <0x27>;
			linux,phandle = <0x27>;
		};

		dwmmc2_tflash_en {
			samsung,pin-function = <0x01>;
			samsung,pins = "gpa0-3";
			samsung,pin-drv = <0x04>;
			samsung,pin-pud = <0x00>;
			samsung,pin-val = <0x01>;
			phandle = <0x5d>;
			linux,phandle = <0x5d>;
		};

		hs-i2c8-bus {
			samsung,pin-function = <0x02>;
			samsung,pins = "gpa2-7\0gpa2-6";
			samsung,pin-drv = <0x00>;
			samsung,pin-pud = <0x03>;
			phandle = <0x42>;
			linux,phandle = <0x42>;
		};

		hs-i2c7-bus {
			samsung,pin-function = <0x02>;
			samsung,pins = "gpa2-5\0gpa2-4";
			samsung,pin-drv = <0x00>;
			samsung,pin-pud = <0x03>;
			phandle = <0x41>;
			linux,phandle = <0x41>;
		};

		cp_gpio_w {
			samsung,pin-function = <0x04>;
			samsung,pins = "gpa2-5\0gpa2-6";
			samsung,pin-pud = <0x00>;
		};

		hs-i2c6-bus {
			samsung,pin-function = <0x02>;
			samsung,pins = "gpa2-2\0gpa2-1";
			samsung,pin-drv = <0x00>;
			samsung,pin-pud = <0x03>;
			phandle = <0x40>;
			linux,phandle = <0x40>;
		};

		hs-i2c5-bus {
			samsung,pin-function = <0x02>;
			samsung,pins = "gpa2-0\0gpa1-7";
			samsung,pin-drv = <0x00>;
			samsung,pin-pud = <0x03>;
			phandle = <0x3f>;
			linux,phandle = <0x3f>;
		};

		key-volup {
			samsung,pin-function = <0x0f>;
			samsung,pins = "gpa0-7";
			samsung,pin-drv = <0x00>;
			samsung,pin-pud = <0x03>;
			phandle = <0x79>;
			linux,phandle = <0x79>;
		};

		sim0_gpio_on5 {
			samsung,pin-function = <0x0f>;
			samsung,pins = "gpa2-4";
			samsung,pin-pud = <0x00>;
			phandle = <0x15>;
			linux,phandle = <0x15>;
		};

		spi3-cs-0 {
			samsung,pin-function = <0x01>;
			samsung,pins = "gpa2-6";
			samsung,pin-drv = <0x00>;
			samsung,pin-pud = <0x03>;
		};

		cp_gpio_tabes_vzw_rev1 {
			samsung,pin-function = <0x04>;
			samsung,pins = "gpa1-7\0gpa2-0\0gpa2-1\0gpa2-2";
			samsung,pin-pud = <0x00>;
		};

		spi2-cs-0 {
			samsung,pin-function = <0x01>;
			samsung,pins = "gpa2-1";
			samsung,pin-drv = <0x00>;
			samsung,pin-pud = <0x03>;
		};

		nfc-clkreq-int {
			samsung,pin-function = <0x00>;
			samsung,pins = "gpa0-6";
			samsung,pin-pud = <0x00>;
		};

		acc_int {
			samsung,pin-function = <0x00>;
			samsung,pins = "gpa2-2";
			samsung,pin-drv = <0x00>;
			samsung,pin-pud = <0x00>;
			phandle = <0x25>;
			linux,phandle = <0x25>;
		};

		fimc-is-flash {
			samsung,pin-function = <0x01>;
			samsung,pins = "gpa0-0";
			samsung,pin-drv = <0x00>;
			samsung,pin-pud = <0x00>;
			phandle = <0x81>;
			linux,phandle = <0x81>;
		};

		cp_gpio_j3neoelte {
			samsung,pin-function = <0x04>;
			samsung,pins = "gpa1-7\0gpa2-2\0gpa2-3\0gpa2-4\0gpa2-5\0gpa2-6\0gpa2-7";
			samsung,pin-pud = <0x00>;
		};

		if-irq {
			samsung,pins = "gpa0-5";
			samsung,pin-drv = <0x03>;
			samsung,pin-pud = <0x03>;
			phandle = <0x47>;
			linux,phandle = <0x47>;
		};

		nfc-int {
			samsung,pin-function = <0x00>;
			samsung,pins = "gpa2-7";
			samsung,pin-pud = <0x01>;
			phandle = <0x36>;
			linux,phandle = <0x36>;
		};

		nfc-clk {
			samsung,pin-function = <0x02>;
			samsung,pins = "gpq0-0";
			samsung,pin-pud = <0x00>;
			phandle = <0x37>;
			linux,phandle = <0x37>;
		};

		cp_gpio_j4lte {
			samsung,pin-function = <0x04>;
			samsung,pins = "gpa2-6";
			samsung,pin-pud = <0x00>;
		};

		cp_gpio_j3pop {
			samsung,pin-function = <0x04>;
			samsung,pins = "gpa2-3";
			samsung,pin-pud = <0x00>;
		};

		cp_gpio_j2corelte {
			samsung,pin-function = <0x04>;
			samsung,pins = "gpa1-7\0gpa2-6\0gpa2-7";
			samsung,pin-pud = <0x00>;
		};

		uart2-sleep {
			samsung,pin-function = <0x00>;
			samsung,pins = "gpa1-6";
			samsung,pin-pud = <0x01>;
			phandle = <0x14>;
			linux,phandle = <0x14>;
		};

		cp_gpio_tabes_vzw {
			samsung,pin-function = <0x04>;
			samsung,pins = "gpa2-0\0gpa2-1\0gpa2-2";
			samsung,pin-pud = <0x00>;
		};

		dwmmc2_cd_ext_irq {
			samsung,pin-function = <0x0f>;
			samsung,pins = "gpa0-1";
			samsung,pin-drv = <0x04>;
			samsung,pin-pud = <0x00>;
			phandle = <0x5c>;
			linux,phandle = <0x5c>;
		};

		cp_gpio_x4 {
			samsung,pin-function = <0x04>;
			samsung,pins = "gpa1-7\0gpa2-0\0gpa2-1\0gpa2-4";
			samsung,pin-pud = <0x00>;
		};

		muic-irq {
			samsung,pins = "gpa1-1";
			samsung,pin-drv = <0x00>;
			samsung,pin-pud = <0x00>;
			phandle = <0x1c>;
			linux,phandle = <0x1c>;
		};

		uart4-bus-dual {
			samsung,pin-function = <0x02>;
			samsung,pins = "gpa2-5\0gpa2-4";
			samsung,pin-pud = <0x00>;
		};

		wakeup-interrupt-controller {
			interrupts = <0x00 0x10 0x00>;
			compatible = "samsung,exynos4210-wakeup-eint";
			samsung,eint-flt-conf;
			interrupt-parent = <0x01>;
		};

		cp_gpio_j3y17_rev1 {
			samsung,pin-function = <0x04>;
			samsung,pins = "gpa1-7\0gpa2-6";
			samsung,pin-pud = <0x00>;
			phandle = <0x8c>;
			linux,phandle = <0x8c>;
		};

		cp_gpio_j3y17_rev0 {
			samsung,pin-function = <0x04>;
			samsung,pins = "gpa1-7\0gpa2-6\0gpa2-5";
			samsung,pin-pud = <0x00>;
		};

		spi3-bus {
			samsung,pin-function = <0x02>;
			samsung,pins = "gpa2-5\0gpa2-4\0gpa2-7";
			samsung,pin-drv = <0x00>;
			samsung,pin-pud = <0x03>;
			phandle = <0x4d>;
			linux,phandle = <0x4d>;
		};

		spi2-bus {
			samsung,pin-function = <0x02>;
			samsung,pins = "gpa2-0\0gpa1-7\0gpa2-2";
			samsung,pin-drv = <0x00>;
			samsung,pin-pud = <0x03>;
			phandle = <0x4c>;
			linux,phandle = <0x4c>;
		};

		fimc_is_mclk1_in {
			samsung,pin-function = <0x00>;
			samsung,pins = "gpa2-3";
			samsung,pin-drv = <0x00>;
			samsung,pin-pud = <0x00>;
		};

		fimc_is_mclk1_fn {
			samsung,pin-function = <0x02>;
			samsung,pins = "gpa2-3";
			samsung,pin-drv = <0x01>;
			samsung,pin-pud = <0x00>;
		};

		tkey-input {
			samsung,pin-function = <0x00>;
			samsung,pins = "gpa0-2";
			samsung,pin-drv = <0x00>;
			samsung,pin-pud = <0x00>;
			phandle = <0x7f>;
			linux,phandle = <0x7f>;
		};

		tkey-irq {
			samsung,pin-function = <0x0f>;
			samsung,pins = "gpa0-2";
			samsung,pin-drv = <0x00>;
			samsung,pin-pud = <0x00>;
			phandle = <0x7e>;
			linux,phandle = <0x7e>;
		};

		cp_gpio {
			samsung,pin-function = <0x04>;
			samsung,pins = "gpa1-7\0gpa2-1";
			samsung,pin-pud = <0x00>;
		};

		gpq0 {
			#gpio-cells = <0x02>;
			#interrupt-cells = <0x02>;
			interrupt-controller;
			gpio-controller;
		};

		gpa2 {
			#gpio-cells = <0x02>;
			#interrupt-cells = <0x02>;
			phandle = <0x18>;
			interrupt-controller;
			gpio-controller;
			linux,phandle = <0x18>;
		};

		gpa1 {
			interrupts = <0x00 0x08 0x00 0x00 0x09 0x00 0x00 0x0a 0x00 0x00 0x0b 0x00 0x00 0x0c 0x00 0x00 0x0d 0x00 0x00 0x0e 0x00 0x00 0x0f 0x00>;
			#gpio-cells = <0x02>;
			#interrupt-cells = <0x03>;
			phandle = <0x17>;
			interrupt-controller;
			gpio-controller;
			linux,phandle = <0x17>;
			interrupt-parent = <0x01>;
		};

		gpa0 {
			interrupts = <0x00 0x00 0x00 0x00 0x01 0x00 0x00 0x02 0x00 0x00 0x03 0x00 0x00 0x04 0x00 0x00 0x05 0x00 0x00 0x06 0x00 0x00 0x07 0x00>;
			#gpio-cells = <0x02>;
			#interrupt-cells = <0x02>;
			phandle = <0x48>;
			interrupt-controller;
			gpio-controller;
			linux,phandle = <0x48>;
			interrupt-parent = <0x01>;
		};

		cp_gpio_on5 {
			samsung,pin-function = <0x04>;
			samsung,pins = "gpa1-7";
			samsung,pin-pud = <0x00>;
		};

		cp_gpio_iot {
			samsung,pin-function = <0x04>;
			samsung,pins = "gpa1-3\0gpa2-0\0gpa2-2\0gpa2-7";
			samsung,pin-pud = <0x00>;
		};

		etc1 {
			#gpio-cells = <0x02>;
			#interrupt-cells = <0x02>;
			interrupt-controller;
			gpio-controller;
		};

		etc0 {
			#gpio-cells = <0x02>;
			#interrupt-cells = <0x02>;
			interrupt-controller;
			gpio-controller;
		};

		fimc_is_mclk1_out {
			samsung,pin-function = <0x01>;
			samsung,pins = "gpa2-3";
			samsung,pin-drv = <0x02>;
			samsung,pin-pud = <0x01>;
		};
	};

	pinctrl@139E0000 {
		reg = <0x00 0x139e0000 0x1000>;
		interrupts = <0x00 0x1b9 0x00>;
		pinctrl-0 = <0x03>;
		compatible = "samsung,exynos7570-pinctrl";
		pinctrl-names = "sleep";

		spi0-cs-1 {
			samsung,pin-function = <0x01>;
			samsung,pins = "gpc7-4";
			samsung,pin-drv = <0x00>;
			samsung,pin-pud = <0x03>;
		};

		spi0-cs-0 {
			samsung,pin-function = <0x01>;
			samsung,pins = "gpc7-1";
			samsung,pin-drv = <0x00>;
			samsung,pin-pud = <0x03>;
		};

		spi0-bus {
			samsung,pin-function = <0x02>;
			samsung,pins = "gpc7-3\0gpc7-2\0gpc7-0";
			samsung,pin-drv = <0x00>;
			samsung,pin-pud = <0x03>;
			phandle = <0x4a>;
			linux,phandle = <0x4a>;
		};

		sleep-state {
			phandle = <0x03>;
			linux,phandle = <0x03>;

			gpc7-4 {
				samsung,pin-pud-pdn = <0x01>;
				samsung,pin-con-pdn = <0x02>;
				samsung,pins = "gpc7-4";
			};

			gpc7-3 {
				samsung,pin-pud-pdn = <0x01>;
				samsung,pin-con-pdn = <0x02>;
				samsung,pins = "gpc7-3";
			};

			gpc7-2 {
				samsung,pin-pud-pdn = <0x01>;
				samsung,pin-con-pdn = <0x02>;
				samsung,pins = "gpc7-2";
			};

			gpc7-1 {
				samsung,pin-pud-pdn = <0x01>;
				samsung,pin-con-pdn = <0x02>;
				samsung,pins = "gpc7-1";
			};

			gpc7-0 {
				samsung,pin-pud-pdn = <0x01>;
				samsung,pin-con-pdn = <0x02>;
				samsung,pins = "gpc7-0";
			};
		};

		gpc7 {
			#gpio-cells = <0x02>;
			#interrupt-cells = <0x02>;
			interrupt-controller;
			gpio-controller;
		};
	};

	pinctrl@139D0000 {
		reg = <0x00 0x139d0000 0x1000>;
		interrupts = <0x00 0x1b8 0x00>;
		pinctrl-0 = <0x09>;
		compatible = "samsung,exynos7570-pinctrl";
		pinctrl-names = "sleep";

		i2c3-bus {
			samsung,pin-function = <0x02>;
			samsung,pins = "gpc3-1\0gpc3-0";
			samsung,pin-drv = <0x00>;
			samsung,pin-pud = <0x01>;
			phandle = <0x1e>;
			linux,phandle = <0x1e>;
		};

		attn-input {
			samsung,pin-function = <0x00>;
			samsung,pins = "gpc3-2";
			samsung,pin-drv = <0x00>;
			samsung,pin-pud = <0x00>;
		};

		i2c-on {
			samsung,pin-function = <0x02>;
			samsung,pins = "gpc3-1\0gpc3-0";
			samsung,pin-drv = <0x00>;
			samsung,pin-pud = <0x00>;
			phandle = <0x20>;
			linux,phandle = <0x20>;
		};

		sleep-state {
			phandle = <0x09>;
			linux,phandle = <0x09>;

			gpc3-2 {
				samsung,pin-pud-pdn = <0x01>;
				samsung,pin-con-pdn = <0x02>;
				samsung,pins = "gpc3-2";
			};

			gpc3-1 {
				samsung,pin-pud-pdn = <0x01>;
				samsung,pin-con-pdn = <0x02>;
				samsung,pins = "gpc3-1";
			};

			gpc3-0 {
				samsung,pin-pud-pdn = <0x01>;
				samsung,pin-con-pdn = <0x02>;
				samsung,pins = "gpc3-0";
			};
		};

		attn-irq {
			samsung,pin-function = <0x0f>;
			samsung,pins = "gpc3-2";
			samsung,pin-drv = <0x00>;
			samsung,pin-pud = <0x00>;
			phandle = <0x1f>;
			linux,phandle = <0x1f>;
		};

		i2c-off {
			samsung,pin-function = <0x02>;
			samsung,pins = "gpc3-1\0gpc3-0";
			samsung,pin-drv = <0x00>;
			samsung,pin-pud = <0x01>;
			phandle = <0x21>;
			linux,phandle = <0x21>;
		};

		gpd2 {
			#gpio-cells = <0x02>;
			#interrupt-cells = <0x02>;
			phandle = <0x76>;
			interrupt-controller;
			gpio-controller;
			linux,phandle = <0x76>;
		};

		gpc3 {
			#gpio-cells = <0x02>;
			#interrupt-cells = <0x02>;
			phandle = <0x22>;
			interrupt-controller;
			gpio-controller;
			linux,phandle = <0x22>;
		};
	};

	pinctrl@139C0000 {
		reg = <0x00 0x139c0000 0x1000>;
		interrupts = <0x00 0x1b7 0x00>;
		pinctrl-0 = <0x06>;
		compatible = "samsung,exynos7570-pinctrl";
		pinctrl-names = "sleep";

		i2c2-bus {
			samsung,pin-function = <0x02>;
			samsung,pins = "gpc2-1\0gpc2-0";
			samsung,pin-drv = <0x00>;
			samsung,pin-pud = <0x00>;
			phandle = <0x1d>;
			linux,phandle = <0x1d>;
		};

		gpio-nfc {
			samsung,pin-con-pdn = <0x03>;
			samsung,pin-function = <0x01>;
			samsung,pins = "gpc2-2";
			samsung,pin-drv = <0x00>;
			samsung,pin-pud = <0x00>;
			samsung,pin-val = <0x01>;
		};

		nfc_pd {
			samsung,pin-function = <0x02>;
			samsung,pins = "gpc2-2";
			samsung,pin-drv = <0x00>;
			samsung,pin-pud = <0x00>;
			phandle = <0x34>;
			linux,phandle = <0x34>;
		};

		nfc_clk_req {
			samsung,pin-function = <0x02>;
			samsung,pins = "gpc2-3";
			samsung,pin-drv = <0x00>;
			samsung,pin-pud = <0x01>;
			phandle = <0x39>;
			linux,phandle = <0x39>;
		};

		sleep-state {
			phandle = <0x06>;
			linux,phandle = <0x06>;

			gpc2-3 {
				samsung,pin-pud-pdn = <0x01>;
				samsung,pin-con-pdn = <0x03>;
				samsung,pins = "gpc2-3";
			};

			gpc2-2 {
				samsung,pin-pud-pdn = <0x00>;
				samsung,pin-con-pdn = <0x03>;
				samsung,pins = "gpc2-2";
			};

			gpc2-1 {
				samsung,pin-pud-pdn = <0x00>;
				samsung,pin-con-pdn = <0x02>;
				samsung,pins = "gpc2-1";
			};

			gpc2-0 {
				samsung,pin-pud-pdn = <0x00>;
				samsung,pin-con-pdn = <0x02>;
				samsung,pins = "gpc2-0";
			};
		};

		gpc2 {
			#gpio-cells = <0x02>;
			#interrupt-cells = <0x02>;
			phandle = <0x32>;
			interrupt-controller;
			gpio-controller;
			linux,phandle = <0x32>;
		};
	};

	pinctrl@139B0000 {
		reg = <0x00 0x139b0000 0x1000>;
		interrupts = <0x00 0x1b6 0x00>;
		pinctrl-0 = <0x07>;
		pinctrl-1 = <0x08>;
		compatible = "samsung,exynos7570-pinctrl";
		pinctrl-names = "default\0sleep";

		i2c5-bus {
			samsung,pin-function = <0x02>;
			samsung,pins = "gpc4-3\0gpc4-2";
			samsung,pin-drv = <0x00>;
			samsung,pin-pud = <0x03>;
			phandle = <0x24>;
			linux,phandle = <0x24>;
		};

		i2c4-bus {
			samsung,pin-function = <0x02>;
			samsung,pins = "gpc4-1\0gpc4-0";
			samsung,pin-drv = <0x00>;
			samsung,pin-pud = <0x03>;
			phandle = <0x23>;
			linux,phandle = <0x23>;
		};

		i2c1-bus {
			samsung,pin-function = <0x02>;
			samsung,pins = "gpc1-3\0gpc1-2";
			samsung,pin-drv = <0x00>;
			samsung,pin-pud = <0x03>;
			phandle = <0x1b>;
			linux,phandle = <0x1b>;
		};

		initial-state {
			phandle = <0x07>;
			linux,phandle = <0x07>;

			gpd1-5 {
				samsung,pin-function = <0x00>;
				samsung,pins = "gpd1-5";
				samsung,pin-drv = <0x00>;
				samsung,pin-pud = <0x01>;
			};

			gpd1-4 {
				samsung,pin-function = <0x00>;
				samsung,pins = "gpd1-4";
				samsung,pin-drv = <0x00>;
				samsung,pin-pud = <0x00>;
			};

			gpd1-3 {
				samsung,pin-function = <0x00>;
				samsung,pins = "gpd1-3";
				samsung,pin-drv = <0x00>;
				samsung,pin-pud = <0x00>;
			};

			gpd1-2 {
				samsung,pin-function = <0x00>;
				samsung,pins = "gpd1-2";
				samsung,pin-drv = <0x00>;
				samsung,pin-pud = <0x00>;
			};

			gpc0-2 {
				samsung,pin-function = <0x00>;
				samsung,pins = "gpc0-2";
				samsung,pin-drv = <0x00>;
				samsung,pin-pud = <0x01>;
			};
		};

		cfg-i2c {
			samsung,pin-function = <0x02>;
			samsung,pins = "gpc4-1\0gpc4-0";
			samsung,pin-drv = <0x00>;
			samsung,pin-pud = <0x00>;
			phandle = <0x7c>;
			linux,phandle = <0x7c>;
		};

		uart1-bus {
			samsung,pin-function = <0x04>;
			samsung,pins = "gpc4-3\0gpc4-2";
			samsung,pin-pud = <0x00>;
			phandle = <0x12>;
			linux,phandle = <0x12>;
		};

		fimc-is-flash-host {
			samsung,pin-function = <0x01>;
			samsung,pins = "gpf3-3";
			samsung,pin-drv = <0x00>;
			samsung,pin-pud = <0x01>;
			phandle = <0x8e>;
			linux,phandle = <0x8e>;
		};

		hs-i2c4-bus {
			samsung,pin-con-pdn = <0x00>;
			samsung,pin-function = <0x02>;
			samsung,pins = "gpf1-1\0gpf1-0";
			samsung,pin-drv = <0x00>;
			samsung,pin-pud = <0x00>;
			phandle = <0x30>;
			linux,phandle = <0x30>;
		};

		hs-i2c3-bus {
			samsung,pin-con-pdn = <0x03>;
			samsung,pin-function = <0x02>;
			samsung,pins = "gpf0-3\0gpf0-2";
			samsung,pin-drv = <0x00>;
			samsung,pin-pud = <0x00>;
			phandle = <0x2f>;
			linux,phandle = <0x2f>;
		};

		hs-i2c2-bus {
			samsung,pin-con-pdn = <0x03>;
			samsung,pin-function = <0x02>;
			samsung,pins = "gpf0-1\0gpf0-0";
			samsung,pin-drv = <0x00>;
			samsung,pin-pud = <0x00>;
			phandle = <0x2d>;
			linux,phandle = <0x2d>;
		};

		hs-i2c1-bus {
			samsung,pin-con-pdn = <0x03>;
			samsung,pin-function = <0x03>;
			samsung,pins = "gpf3-2\0gpf3-3";
			samsung,pin-drv = <0x00>;
			samsung,pin-pud = <0x03>;
			phandle = <0x2c>;
			linux,phandle = <0x2c>;
		};

		hs-i2c0-bus {
			samsung,pin-con-pdn = <0x03>;
			samsung,pin-function = <0x03>;
			samsung,pins = "gpf3-0\0gpf3-1";
			samsung,pin-drv = <0x00>;
			samsung,pin-pud = <0x03>;
		};

		pwm-tout1 {
			samsung,pin-function = <0x02>;
			samsung,pins = "gpc0-2";
			samsung,pin-drv = <0x00>;
			samsung,pin-pud = <0x01>;
		};

		pwm-tout0 {
			samsung,pin-function = <0x02>;
			samsung,pins = "gpc0-1";
			samsung,pin-drv = <0x00>;
			samsung,pin-pud = <0x01>;
		};

		decon_te_on {
			samsung,pin-function = <0x02>;
			samsung,pins = "gpe0-2";
		};

		spi1-cs-1 {
			samsung,pin-function = <0x01>;
			samsung,pins = "gpd1-0";
			samsung,pin-drv = <0x00>;
			samsung,pin-pud = <0x03>;
		};

		spi1-cs-0 {
			samsung,pin-function = <0x01>;
			samsung,pins = "gpf3-1";
			samsung,pin-drv = <0x00>;
			samsung,pin-pud = <0x03>;
		};

		nfc_firm {
			samsung,pin-function = <0x01>;
			samsung,pins = "gpf3-2";
			samsung,pin-pud = <0x00>;
			samsung,pin-val = <0x00>;
			phandle = <0x35>;
			linux,phandle = <0x35>;
		};

		spk-amp-i2c {
			samsung,pin-function = <0x03>;
			samsung,pins = "gpf3-0\0gpf3-1";
			samsung,pin-drv = <0x00>;
			samsung,pin-pud = <0x03>;
			phandle = <0x2a>;
			linux,phandle = <0x2a>;
		};

		fimc-is-flash-is {
			samsung,pin-function = <0x01>;
			samsung,pins = "gpf3-3";
			samsung,pin-drv = <0x00>;
			samsung,pin-pud = <0x01>;
			phandle = <0x8d>;
			linux,phandle = <0x8d>;
		};

		fm-lna-en {
			samsung,pin-function = <0x01>;
			samsung,pins = "gpd1-0";
			samsung,pin-pud = <0x00>;
			samsung,pin-val = <0x00>;
			phandle = <0x75>;
			linux,phandle = <0x75>;
		};

		nfc-pwr-en {
			samsung,pin-function = <0x01>;
			samsung,pins = "gpf1-0";
			samsung,pin-pud = <0x00>;
		};

		decon_te_off {
			samsung,pin-function = <0x00>;
			samsung,pins = "gpe0-2";
		};

		nfc_pvdd_en {
			samsung,pin-function = <0x01>;
			samsung,pins = "gpc0-1";
			samsung,pin-pud = <0x00>;
			samsung,pin-val = <0x00>;
			phandle = <0x38>;
			linux,phandle = <0x38>;
		};

		spi1-bus {
			samsung,pin-function = <0x02>;
			samsung,pins = "gpf3-3\0gpf3-2\0gpf3-0";
			samsung,pin-drv = <0x00>;
			samsung,pin-pud = <0x03>;
			phandle = <0x4b>;
			linux,phandle = <0x4b>;
		};

		sleep-state {
			phandle = <0x08>;
			linux,phandle = <0x08>;

			gpf3-3 {
				samsung,pin-pud-pdn = <0x00>;
				samsung,pin-con-pdn = <0x03>;
				samsung,pins = "gpf3-3";
			};

			gpf3-2 {
				samsung,pin-pud-pdn = <0x00>;
				samsung,pin-con-pdn = <0x03>;
				samsung,pins = "gpf3-2";
			};

			gpf3-1 {
				samsung,pin-pud-pdn = <0x03>;
				samsung,pin-con-pdn = <0x02>;
				samsung,pins = "gpf3-1";
			};

			gpf3-0 {
				samsung,pin-pud-pdn = <0x03>;
				samsung,pin-con-pdn = <0x02>;
				samsung,pins = "gpf3-0";
			};

			gpf1-1 {
				samsung,pin-pud-pdn = <0x00>;
				samsung,pin-con-pdn = <0x03>;
				samsung,pins = "gpf1-1";
			};

			gpf1-0 {
				samsung,pin-pud-pdn = <0x00>;
				samsung,pin-con-pdn = <0x03>;
				samsung,pins = "gpf1-0";
			};

			gpf0-3 {
				samsung,pin-pud-pdn = <0x01>;
				samsung,pin-con-pdn = <0x02>;
				samsung,pins = "gpf0-3";
			};

			gpf0-2 {
				samsung,pin-pud-pdn = <0x01>;
				samsung,pin-con-pdn = <0x02>;
				samsung,pins = "gpf0-2";
			};

			gpf0-1 {
				samsung,pin-pud-pdn = <0x01>;
				samsung,pin-con-pdn = <0x02>;
				samsung,pins = "gpf0-1";
			};

			gpf0-0 {
				samsung,pin-pud-pdn = <0x01>;
				samsung,pin-con-pdn = <0x02>;
				samsung,pins = "gpf0-0";
			};

			gpe0-2 {
				samsung,pin-pud-pdn = <0x01>;
				samsung,pin-con-pdn = <0x02>;
				samsung,pins = "gpe0-2";
			};

			gpe0-1 {
				samsung,pin-pud-pdn = <0x01>;
				samsung,pin-con-pdn = <0x02>;
				samsung,pins = "gpe0-1";
			};

			gpe0-0 {
				samsung,pin-pud-pdn = <0x01>;
				samsung,pin-con-pdn = <0x02>;
				samsung,pins = "gpe0-0";
			};

			gpd1-6 {
				samsung,pin-pud-pdn = <0x01>;
				samsung,pin-con-pdn = <0x02>;
				samsung,pins = "gpd1-6";
			};

			gpd1-5 {
				samsung,pin-pud-pdn = <0x01>;
				samsung,pin-con-pdn = <0x02>;
				samsung,pins = "gpd1-5";
			};

			gpd1-4 {
				samsung,pin-pud-pdn = <0x00>;
				samsung,pin-con-pdn = <0x02>;
				samsung,pins = "gpd1-4";
			};

			gpd1-3 {
				samsung,pin-pud-pdn = <0x00>;
				samsung,pin-con-pdn = <0x02>;
				samsung,pins = "gpd1-3";
			};

			gpd1-2 {
				samsung,pin-pud-pdn = <0x00>;
				samsung,pin-con-pdn = <0x02>;
				samsung,pins = "gpd1-2";
			};

			gpd1-1 {
				samsung,pin-pud-pdn = <0x01>;
				samsung,pin-con-pdn = <0x02>;
				samsung,pins = "gpd1-1";
			};

			gpd1-0 {
				samsung,pin-pud-pdn = <0x00>;
				samsung,pin-con-pdn = <0x03>;
				samsung,pins = "gpd1-0";
			};

			gpc4-3 {
				samsung,pin-pud-pdn = <0x03>;
				samsung,pin-con-pdn = <0x02>;
				samsung,pins = "gpc4-3";
			};

			gpc4-2 {
				samsung,pin-pud-pdn = <0x03>;
				samsung,pin-con-pdn = <0x02>;
				samsung,pins = "gpc4-2";
			};

			gpc4-1 {
				samsung,pin-pud-pdn = <0x00>;
				samsung,pin-con-pdn = <0x02>;
				samsung,pins = "gpc4-1";
			};

			gpc4-0 {
				samsung,pin-pud-pdn = <0x00>;
				samsung,pin-con-pdn = <0x02>;
				samsung,pins = "gpc4-0";
			};

			gpc1-3 {
				samsung,pin-pud-pdn = <0x03>;
				samsung,pin-con-pdn = <0x03>;
				samsung,pins = "gpc1-3";
			};

			gpc1-2 {
				samsung,pin-pud-pdn = <0x03>;
				samsung,pin-con-pdn = <0x03>;
				samsung,pins = "gpc1-2";
			};

			gpc0-2 {
				samsung,pin-pud-pdn = <0x01>;
				samsung,pin-con-pdn = <0x02>;
				samsung,pins = "gpc0-2";
			};

			gpc0-1 {
				samsung,pin-pud-pdn = <0x00>;
				samsung,pin-con-pdn = <0x03>;
				samsung,pins = "gpc0-1";
			};
		};

		fimc_is_mclk0_in {
			samsung,pin-function = <0x00>;
			samsung,pins = "gpe0-0";
			samsung,pin-drv = <0x00>;
			samsung,pin-pud = <0x00>;
			phandle = <0x80>;
			linux,phandle = <0x80>;
		};

		fimc_is_mclk0_fn {
			samsung,pin-function = <0x02>;
			samsung,pins = "gpe0-0";
			samsung,pin-drv = <0x01>;
			samsung,pin-pud = <0x00>;
			phandle = <0x82>;
			linux,phandle = <0x82>;
		};

		ese_pvdd_en {
			samsung,pin-function = <0x01>;
			samsung,pins = "gpf1-1";
			samsung,pin-pud = <0x01>;
			samsung,pin-val = <0x00>;
		};

		gpf3 {
			#gpio-cells = <0x02>;
			#interrupt-cells = <0x02>;
			phandle = <0x2b>;
			interrupt-controller;
			gpio-controller;
			linux,phandle = <0x2b>;
		};

		gpf1 {
			#gpio-cells = <0x02>;
			#interrupt-cells = <0x02>;
			phandle = <0x31>;
			interrupt-controller;
			gpio-controller;
			linux,phandle = <0x31>;
		};

		gpf0 {
			#gpio-cells = <0x02>;
			#interrupt-cells = <0x02>;
			phandle = <0x2e>;
			interrupt-controller;
			gpio-controller;
			linux,phandle = <0x2e>;
		};

		gpe0 {
			#gpio-cells = <0x02>;
			#interrupt-cells = <0x02>;
			interrupt-controller;
			gpio-controller;
		};

		gpd1 {
			#gpio-cells = <0x02>;
			#interrupt-cells = <0x02>;
			phandle = <0x74>;
			interrupt-controller;
			gpio-controller;
			linux,phandle = <0x74>;
		};

		gpc4 {
			#gpio-cells = <0x02>;
			#interrupt-cells = <0x02>;
			phandle = <0x7b>;
			interrupt-controller;
			gpio-controller;
			linux,phandle = <0x7b>;
		};

		gpc1 {
			#gpio-cells = <0x02>;
			#interrupt-cells = <0x02>;
			interrupt-controller;
			gpio-controller;
		};

		gpc0 {
			#gpio-cells = <0x02>;
			#interrupt-cells = <0x02>;
			phandle = <0x33>;
			interrupt-controller;
			gpio-controller;
			linux,phandle = <0x33>;
		};

		cfg-gpio {
			samsung,pin-function = <0x00>;
			samsung,pins = "gpc4-1\0gpc4-0";
			samsung,pin-drv = <0x00>;
			samsung,pin-pud = <0x00>;
			phandle = <0x7d>;
			linux,phandle = <0x7d>;
		};

		fimc_is_mclk0_out {
			samsung,pin-function = <0x01>;
			samsung,pins = "gpe0-0";
			samsung,pin-drv = <0x02>;
			samsung,pin-pud = <0x01>;
		};
	};

	pinctrl@13750000 {
		reg = <0x00 0x13750000 0x1000>;
		interrupts = <0x00 0xfa 0x00>;
		pinctrl-0 = <0x05>;
		compatible = "samsung,exynos7570-pinctrl";
		pinctrl-names = "sleep";

		sd0-clk_fast_slew_rate_4x {
			samsung,pin-function = <0x02>;
			samsung,pins = "gpr0-0";
			samsung,pin-drv = <0x03>;
			samsung,pin-pud = <0x00>;
			phandle = <0x57>;
			linux,phandle = <0x57>;
		};

		sd0-clk_fast_slew_rate_3x {
			samsung,pin-function = <0x02>;
			samsung,pins = "gpr0-0";
			samsung,pin-drv = <0x02>;
			samsung,pin-pud = <0x00>;
			phandle = <0x56>;
			linux,phandle = <0x56>;
		};

		sd0-clk_fast_slew_rate_2x {
			samsung,pin-function = <0x02>;
			samsung,pins = "gpr0-0";
			samsung,pin-drv = <0x01>;
			samsung,pin-pud = <0x00>;
			phandle = <0x55>;
			linux,phandle = <0x55>;
		};

		sd0-clk_fast_slew_rate_1x {
			samsung,pin-function = <0x02>;
			samsung,pins = "gpr0-0";
			samsung,pin-drv = <0x00>;
			samsung,pin-pud = <0x00>;
			phandle = <0x54>;
			linux,phandle = <0x54>;
		};

		sd2-bus-width4 {
			samsung,pin-function = <0x02>;
			samsung,pins = "gpr4-3\0gpr4-4\0gpr4-5";
			samsung,pin-drv = <0x02>;
			samsung,pin-pud = <0x03>;
			phandle = <0x5b>;
			linux,phandle = <0x5b>;
		};

		sd2-bus-width1 {
			samsung,pin-function = <0x02>;
			samsung,pins = "gpr4-2";
			samsung,pin-drv = <0x02>;
			samsung,pin-pud = <0x03>;
			phandle = <0x5a>;
			linux,phandle = <0x5a>;
		};

		sd0-rdqs {
			samsung,pin-function = <0x02>;
			samsung,pins = "gpr0-2";
			samsung,pin-drv = <0x02>;
			samsung,pin-pud = <0x01>;
			phandle = <0x50>;
			linux,phandle = <0x50>;
		};

		sd0-bus-width8 {
			samsung,pin-function = <0x02>;
			samsung,pins = "gpr1-4\0gpr1-5\0gpr1-6\0gpr1-7";
			samsung,pin-drv = <0x02>;
			samsung,pin-pud = <0x03>;
			phandle = <0x53>;
			linux,phandle = <0x53>;
		};

		sd0-bus-width4 {
			samsung,pin-function = <0x02>;
			samsung,pins = "gpr1-1\0gpr1-2\0gpr1-3";
			samsung,pin-drv = <0x02>;
			samsung,pin-pud = <0x03>;
			phandle = <0x52>;
			linux,phandle = <0x52>;
		};

		sd0-bus-width1 {
			samsung,pin-function = <0x02>;
			samsung,pins = "gpr1-0";
			samsung,pin-drv = <0x02>;
			samsung,pin-pud = <0x03>;
			phandle = <0x51>;
			linux,phandle = <0x51>;
		};

		sd2-cmd {
			samsung,pin-function = <0x02>;
			samsung,pins = "gpr4-1";
			samsung,pin-drv = <0x02>;
			samsung,pin-pud = <0x03>;
			phandle = <0x59>;
			linux,phandle = <0x59>;
		};

		sd2-clk {
			samsung,pin-function = <0x02>;
			samsung,pins = "gpr4-0";
			samsung,pin-drv = <0x02>;
			samsung,pin-pud = <0x00>;
			phandle = <0x58>;
			linux,phandle = <0x58>;
		};

		sd0-cmd {
			samsung,pin-function = <0x02>;
			samsung,pins = "gpr0-1";
			samsung,pin-drv = <0x02>;
			samsung,pin-pud = <0x03>;
			phandle = <0x4f>;
			linux,phandle = <0x4f>;
		};

		sd0-clk {
			samsung,pin-function = <0x02>;
			samsung,pins = "gpr0-0";
			samsung,pin-drv = <0x02>;
			samsung,pin-pud = <0x00>;
			phandle = <0x4e>;
			linux,phandle = <0x4e>;
		};

		sleep-state {
			phandle = <0x05>;
			linux,phandle = <0x05>;

			gpr0-1 {
				samsung,pin-pud-pdn = <0x00>;
				samsung,pin-con-pdn = <0x02>;
				samsung,pins = "gpr0-1";
			};
		};

		sd2-clk_fast_slew_rate_4x {
			samsung,pin-function = <0x02>;
			samsung,pins = "gpr4-0";
			samsung,pin-drv = <0x03>;
			samsung,pin-pud = <0x00>;
			phandle = <0x61>;
			linux,phandle = <0x61>;
		};

		sd2-clk_fast_slew_rate_3x {
			samsung,pin-function = <0x02>;
			samsung,pins = "gpr4-0";
			samsung,pin-drv = <0x02>;
			samsung,pin-pud = <0x00>;
			phandle = <0x60>;
			linux,phandle = <0x60>;
		};

		sd2-clk_fast_slew_rate_2x {
			samsung,pin-function = <0x02>;
			samsung,pins = "gpr4-0";
			samsung,pin-drv = <0x01>;
			samsung,pin-pud = <0x00>;
			phandle = <0x5f>;
			linux,phandle = <0x5f>;
		};

		sd2-clk_fast_slew_rate_1x {
			samsung,pin-function = <0x02>;
			samsung,pins = "gpr4-0";
			samsung,pin-drv = <0x00>;
			samsung,pin-pud = <0x00>;
			phandle = <0x5e>;
			linux,phandle = <0x5e>;
		};

		gpr4 {
			#gpio-cells = <0x02>;
			#interrupt-cells = <0x02>;
			interrupt-controller;
			gpio-controller;
		};

		gpr1 {
			#gpio-cells = <0x02>;
			#interrupt-cells = <0x02>;
			interrupt-controller;
			gpio-controller;
		};

		gpr0 {
			#gpio-cells = <0x02>;
			#interrupt-cells = <0x02>;
			interrupt-controller;
			gpio-controller;
		};
	};

	pinctrl@10530000 {
		reg = <0x00 0x10530000 0x1000>;
		interrupts = <0x00 0x188 0x00>;
		compatible = "samsung,exynos7570-pinctrl";

		speedy-bus {
			samsung,pin-con-pdn = <0x03>;
			samsung,pin-function = <0x02>;
			samsung,pins = "gpm0-0";
			samsung,pin-drv = <0x00>;
			phandle = <0x43>;
			linux,phandle = <0x43>;
		};

		gpm0 {
			#gpio-cells = <0x02>;
			#interrupt-cells = <0x02>;
			interrupt-controller;
			gpio-controller;
		};
	};

	phy_phy_csis@144F1040 {
		reg = <0x00 0x144f1040 0x04>;
		reset = <0x01 0x00>;
		compatible = "samsung,mipi-phy-csis";
		#phy-cells = <0x01>;
		isolation = <0x70c 0x714>;
		samsung,pmu-syscon = <0x0f>;
		phandle = <0x72>;
		linux,phandle = <0x72>;
	};

	phy_m4s4_dsi@148F100C {
		reg = <0x00 0x148f100c 0x04>;
		reset = <0x00>;
		compatible = "samsung,mipi-phy-dsim";
		#phy-cells = <0x01>;
		isolation = <0x70c>;
		samsung,pmu-syscon = <0x0f>;
		phandle = <0x63>;
		linux,phandle = <0x63>;
	};

	pd-mfcmscl@11C84060 {
		reg = <0x00 0x11c84060 0x20>;
		compatible = "samsung,exynos-pd";
		cal_id = <0xb1380008>;
		status = "okay";
		phandle = <0x0a>;
		linux,phandle = <0x0a>;
	};

	pd-isp@11C84040 {
		reg = <0x00 0x11c84040 0x20>;
		compatible = "samsung,exynos-pd";
		devfreq-sync-voltage = <0x03>;
		cal_id = <0xb1380003>;
		parent = <0x0a>;
		status = "okay";
		phandle = <0x0c>;
		linux,phandle = <0x0c>;
	};

	pd-g3d@11C84000 {
		reg = <0x00 0x11c84000 0x20>;
		compatible = "samsung,exynos-pd";
		cal_id = <0xb1380000>;
		status = "okay";
		phandle = <0x0d>;
		linux,phandle = <0x0d>;
	};

	pd-dispaud@11C84020 {
		reg = <0x00 0x11c84020 0x20>;
		compatible = "samsung,exynos-pd";
		cal_id = <0xb138000d>;
		status = "okay";
		check-cp-status = "true";
		phandle = <0x0b>;
		linux,phandle = <0x0b>;

		spd-fm@11C84020 {
			compatible = "samsung,exynos-spd";
			phandle = <0x73>;
			linux,phandle = <0x73>;
		};

		spd-disp@11C84020 {
			compatible = "samsung,exynos-spd";
			phandle = <0x62>;
			linux,phandle = <0x62>;
		};

		spd-aud@11C84020 {
			compatible = "samsung,exynos-spd";
			phandle = <0x3a>;
			linux,phandle = <0x3a>;
		};
	};

	muic {
		status = "okay";
		muic,support-list = "+OTG:GND\0-MHL:1K\0-VZW Accessory:28.7K\0-VZW Incompatible:34K\0-Smartdock:40.2K\0-HMT:49.9K\0-Audiodock:64.9K\0-USB LANHUB:80.07K\0-Charging Cable:102K\0-Universal Multimedia dock:121K\0+Jig USB Off:255K\0+Jig USB On:301K\0+Deskdock:365K\0+TYPE2 Charger:442K\0+Jig UART Off:523K\0+Jig UART On:619K\0+TA:OPEN\0+USB:OPEN\0+CDP:OPEN\0+Undefined Charging:XXX";
	};

	mif_pdata {
		reg = <0x00 0x10000 0x00>;
		interrupts = <0x00 0x12 0x00 0x00 0x1df 0x00>;
		mif,ipc_version = <0x32>;
		mif,modem_net = <0x00>;
		pinctrl-0 = <0x8c>;
		mbx_ap2cp_cp_voltage_700 = <0x05>;
		mbx_ap2cp_cp_voltage_830 = <0x07>;
		mif,irq_cp2ap_wake_lock = <0x08>;
		mif,irq_cp2ap_msg = <0x00>;
		compatible = "sec_modem,modem_pdata";
		sbi_lte_active_mask = <0x01>;
		mif,irq_cp2ap_perf_req_mif = <0x06>;
		mif,int_ap2cp_status = <0x02>;
		mif,irq_cp2ap_active = <0x03>;
		sbi_ds_det_pos = <0x0e>;
		sbi_pda_active_pos = <0x05>;
		mbx_cp2ap_dvfsreq = <0x04>;
		mif,int_ap2cp_msg = <0x00>;
		sbi_cp_status_pos = <0x01>;
		mbx_ap2cp_united_status = <0x02>;
		sbi_ap_status_mask = <0x0f>;
		mif,name = "ss305ap";
		mif,link_name = "shmem";
		mif,modem_type = <0x0a>;
		mif,link_attrs = <0x7c8>;
		mif,link_types = <0x200>;
		mif,irq_cp2ap_status = <0x02>;
		sbi_evs_mode_pos = <0x07>;
		sbi_sys_rev_pos = <0x06>;
		sbi_cp_cpu_freq_asv_pos = <0x13>;
		sbi_evs_mode_mask = <0x01>;
		sbi_sys_rev_mask = <0xff>;
		mif,num_iodevs = <0x13>;
		status = "okay";
		mif,use_handover = <0x00>;
		mbx_cp2ap_dvfsreq_mif = <0x06>;
		mbx_cp2ap_united_status = <0x03>;
		sbi_lte_active_pos = <0x05>;
		sbi_ap_status_pos = <0x01>;
		mbx_ap2cp_msg = <0x00>;
		sbi_cp_status_mask = <0x0f>;
		sbi_ds_det_mask = <0x03>;
		sbi_pda_active_mask = <0x01>;
		sbi_cp_cpu_freq_asv_mask = <0x07>;
		pinctrl-names = "default";
		mif,int_ap2cp_active = <0x03>;
		mbx_cp2ap_msg = <0x01>;

		iodevs {

			io_device_9 {
				iod,attrs = <0x02>;
				iod,links = <0x200>;
				iod,io_type = <0x01>;
				iod,format = <0x01>;
				iod,id = <0x0d>;
				iod,name = "rmnet3";
				iod,app = "NET";
			};

			io_device_8 {
				iod,attrs = <0x02>;
				iod,links = <0x200>;
				iod,io_type = <0x01>;
				iod,format = <0x01>;
				iod,id = <0x0c>;
				iod,name = "rmnet2";
				iod,app = "NET";
			};

			io_device_7 {
				iod,attrs = <0x02>;
				iod,links = <0x200>;
				iod,io_type = <0x01>;
				iod,format = <0x01>;
				iod,id = <0x0b>;
				iod,name = "rmnet1";
				iod,app = "NET";
			};

			io_device_6 {
				iod,attrs = <0x02>;
				iod,links = <0x200>;
				iod,io_type = <0x01>;
				iod,format = <0x01>;
				iod,id = <0x0a>;
				iod,name = "rmnet0";
				iod,app = "NET";
			};

			io_device_5 {
				iod,attrs = <0x02>;
				iod,links = <0x200>;
				iod,io_type = <0x00>;
				iod,format = <0x01>;
				iod,id = <0x1c>;
				iod,name = "umts_dm0";
				iod,app = "DIAG";
			};

			io_device_4 {
				iod,attrs = <0x02>;
				iod,links = <0x200>;
				iod,max_tx_size = <0x800>;
				iod,io_type = <0x00>;
				iod,format = <0x01>;
				iod,id = <0x19>;
				iod,name = "umts_router";
				iod,app = "Data Router";
			};

			io_device_3 {
				iod,attrs = <0x02>;
				iod,links = <0x200>;
				iod,io_type = <0x00>;
				iod,format = <0x01>;
				iod,id = <0x01>;
				iod,name = "umts_csd";
				iod,app = "CSVT";
			};

			io_device_2 {
				iod,attrs = <0x02>;
				iod,links = <0x200>;
				iod,io_type = <0x00>;
				iod,format = <0x02>;
				iod,id = <0xf5>;
				iod,name = "umts_rfs0";
				iod,app = "RFS";
			};

			io_device_1 {
				iod,attrs = <0x02>;
				iod,links = <0x200>;
				iod,io_type = <0x00>;
				iod,format = <0x00>;
				iod,id = <0xec>;
				iod,name = "umts_ipc1";
				iod,app = "RIL";
			};

			io_device_0 {
				iod,attrs = <0x02>;
				iod,links = <0x200>;
				iod,io_type = <0x00>;
				iod,format = <0x00>;
				iod,id = <0xeb>;
				iod,name = "umts_ipc0";
				iod,app = "RIL";
			};

			io_device_18 {
				iod,attrs = <0x802>;
				iod,links = <0x200>;
				iod,option_region = "usa_att";
				iod,io_type = <0x00>;
				iod,format = <0x01>;
				iod,id = <0x1a>;
				iod,name = "umts_ciq0";
			};

			io_device_17 {
				iod,attrs = <0x802>;
				iod,links = <0x200>;
				iod,option_region = "kor_skt";
				iod,io_type = <0x00>;
				iod,format = <0x01>;
				iod,id = <0x21>;
				iod,name = "smd4";
			};

			io_device_16 {
				iod,attrs = <0x202>;
				iod,links = <0x200>;
				iod,io_type = <0x00>;
				iod,format = <0x05>;
				iod,id = <0xe1>;
				iod,name = "umts_ramdump0";
				iod,app = "CBD";
			};

			io_device_15 {
				iod,attrs = <0x02>;
				iod,links = <0x200>;
				iod,io_type = <0x00>;
				iod,format = <0x04>;
				iod,id = <0xd7>;
				iod,name = "umts_boot0";
				iod,app = "CBD";
			};

			io_device_14 {
				iod,attrs = <0x02>;
				iod,links = <0x200>;
				iod,io_type = <0x02>;
				iod,format = <0x03>;
				iod,id = <0x00>;
				iod,name = "multipdp";
				iod,app = "RIL";
			};

			io_device_13 {
				iod,attrs = <0x02>;
				iod,links = <0x200>;
				iod,io_type = <0x01>;
				iod,format = <0x01>;
				iod,id = <0x11>;
				iod,name = "rmnet7";
			};

			io_device_12 {
				iod,attrs = <0x02>;
				iod,links = <0x200>;
				iod,io_type = <0x01>;
				iod,format = <0x01>;
				iod,id = <0x10>;
				iod,name = "rmnet6";
			};

			io_device_11 {
				iod,attrs = <0x02>;
				iod,links = <0x200>;
				iod,io_type = <0x01>;
				iod,format = <0x01>;
				iod,id = <0x0f>;
				iod,name = "rmnet5";
			};

			io_device_10 {
				iod,attrs = <0x02>;
				iod,links = <0x200>;
				iod,io_type = <0x01>;
				iod,format = <0x01>;
				iod,id = <0x0e>;
				iod,name = "rmnet4";
			};
		};
	};

	mfc0@12C30000 {
		reg = <0x00 0x12c30000 0x10000>;
		interrupts = <0x00 0x162 0x00>;
		compatible = "samsung,mfc-v6";
		clock-names = "aclk_mfc";
		clocks = <0x11 0x264>;
		ip_ver = <0x11>;
		min_rate = <0x186a0>;
		num_qos_steps = <0x02>;
		status = "ok";
		#pb-id-cells = <0x00>;
		phandle = <0x69>;
		clock_rate = <0x18bc65c0>;
		samsung,power-domain = <0x0a>;
		linux,phandle = <0x69>;

		mfc_qos_table {

			mfc_qos_variant_1 {
				thrd_mb = <0x3bc40>;
				freq_cpu = <0x00>;
				freq_int = <0x65518>;
				freq_kfc = <0x00>;
				freq_mfc = <0x00>;
				freq_mif = <0xa2990>;
				has_enc_table = <0x00>;
			};

			mfc_qos_variant_0 {
				thrd_mb = <0x00>;
				freq_cpu = <0x00>;
				freq_int = <0x65518>;
				freq_kfc = <0x00>;
				freq_mfc = <0x00>;
				freq_mif = <0x65518>;
				has_enc_table = <0x00>;
			};
		};
	};

	memory@80000000 {
		reg = <0x00 0x80000000 0x40000000>;
		device_type = "memory";
	};

	memory@40000000 {
		reg = <0x00 0x40000000 0x3e800000>;
		device_type = "memory";
	};

	mdev_output {
		compatible = "samsung,exynos5-mdev";
	};

	mcu_ipc@10570000 {
		reg = <0x00 0x10570000 0x180>;
		interrupts = <0x00 0x175 0x00>;
		compatible = "samsung,exynos-shd-ipc-mailbox";
		mcu,id = <0x01>;
		mcu,name = "mcu_ipc_gnss";
	};

	mcu_ipc@10500000 {
		reg = <0x00 0x10500000 0x180>;
		interrupts = <0x00 0x171 0x00>;
		mcu,irq_affinity_mask = <0x03>;
		compatible = "samsung,exynos-shd-ipc-mailbox";
		mcu,id = <0x00>;
		mcu,name = "mcu_ipc_cp";
	};

	mct@101B0000 {
		reg = <0x00 0x101b0000 0x800>;
		interrupts = <0x00 0x01 0x02 0x03 0x04 0x05 0x06 0x07 0x08 0x09 0x0a 0x0b>;
		compatible = "samsung,exynos4210-mct";
		clock-names = "fin_pll\0mct";
		use-clockevent-only;
		clocks = <0x11 0x01 0x11 0x172>;
		#interrupt-cells = <0x01>;
		interrupt-controller;
		interrupt-parent = <0x10>;

		mct-map {
			#interrupt-cells = <0x01>;
			#address-cells = <0x00>;
			interrupt-map = <0x00 0x01 0x00 0x66 0x00 0x01 0x01 0x00 0x67 0x00 0x02 0x01 0x00 0x68 0x00 0x03 0x01 0x00 0x69 0x00 0x04 0x01 0x00 0x6a 0x00 0x05 0x01 0x00 0x6b 0x00 0x06 0x01 0x00 0x6c 0x00 0x07 0x01 0x00 0x6d 0x00 0x08 0x01 0x00 0x6e 0x00 0x09 0x01 0x00 0x6f 0x00 0x0a 0x01 0x00 0x70 0x00 0x0b 0x01 0x00 0x71 0x00>;
			phandle = <0x10>;
			#size-cells = <0x00>;
			linux,phandle = <0x10>;
		};
	};

	mali@11400000 {
		reg = <0x00 0x11400000 0x5000>;
		interrupts = <0x00 0x11a 0x00 0x00 0x11b 0x00 0x00 0x119 0x00>;
		compatible = "arm,mali";
		clock-names = "vclk_g3d";
		interrupt-names = "JOB\0MMU\0GPU";
		clocks = <0x11 0xcb>;
		samsung,power-domain = <0x0d>;
	};

	lpass@148F0000 {
		reg = <0x00 0x148f0000 0x1040>;
		compatible = "samsung,exynos7570-lpass";
		clock-names = "fout_aud_pll\0dout_sclk_mi2s\0dispaud_decon";
		clocks = <0x11 0x2e4 0x11 0x2c7 0x11 0x2bf>;
		status = "okay";
		samsung,syscon-phandle = <0x0f>;
		samsung,power-domain = <0x3a>;
	};

	leds_ktd2692 {
		pinctrl-0 = <0x8d>;
		pinctrl-1 = <0x8e>;
		pinctrl-2 = <0x8d>;
		compatible = "ktd2692";
		flash_control = <0x2b 0x03 0x01>;
		status = "okay";
		pinctrl-names = "default\0host\0is";
	};

	ion {
		compatible = "samsung,exynos5430-ion";
	};

	iommu-domain_mfc_mscl {
		compatible = "samsung,exynos-iommu-bus";
		domain-clients = <0x67 0x68 0x69 0x6a 0x6b 0x6c>;
		ranges;
		#address-cells = <0x02>;
		#size-cells = <0x01>;

		smfc@12C20000 {
			reg = <0x00 0x12c20000 0x2000>;
			interrupts = <0x00 0x194 0x00>;
			compatible = "samsung,exynos8890-jpeg";
			clock-names = "gate";
			clocks = <0x11 0x263>;
			phandle = <0x67>;
			samsung,power-domain = <0x0a>;
			linux,phandle = <0x67>;
		};

		sysmmu@12C80000 {
			reg = <0x00 0x12c80000 0x3000>;
			interrupts = <0x00 0x160 0x00 0x00 0x199 0x00>;
			master_ip_list = <0x67 0x68 0x69 0x6a>;
			sysmmu,secure_reg = <0x12c70000>;
			compatible = "samsung,exynos7420-sysmmu";
			clock-names = "aclk";
			sysmmu,handle_secure-irq;
			clocks = <0x11 0x44c>;
			sysmmu,v7tlb_property = <0x02 0x4a 0x06 0x4a 0x0e 0x46 0x8022 0x46 0x8026 0x46 0x802a 0x46>;
			samsung,power-domain = <0x0a>;
		};

		scaler@12C10000 {
			reg = <0x00 0x12c10000 0x1300>;
			interrupts = <0x00 0x191 0x00>;
			compatible = "samsung,exynos5-scaler";
			clock-names = "gate";
			clocks = <0x11 0x262>;
			prefetch-buffer,disable;
			phandle = <0x68>;
			samsung,power-domain = <0x0a>;
			linux,phandle = <0x68>;
		};

		sysmmu@0x14470000 {
			reg = <0x00 0x14470000 0x3000>;
			qos = <0x0f>;
			interrupts = <0x00 0x80 0x00>;
			master_ip_list = <0x6a 0x6b 0x6c>;
			compatible = "samsung,exynos7420-sysmmu";
			clock-names = "aclk";
			clocks = <0x11 0x44e>;
			sysmmu,v7tlb_property = <0x8000 0x0a 0x8004 0x0a 0x01 0x0a 0x8001 0x0a 0x8005 0x0a 0x8002 0x0a 0x8006 0x0a 0x800a 0x0a 0x8003 0x0a 0x03 0x20>;
			samsung,power-domain = <0x0c>;
		};
	};

	iommu-domain_disp {
		compatible = "samsung,exynos-iommu-bus";
		domain-clients = <0x6d>;
		ranges;
		#address-cells = <0x02>;
		#size-cells = <0x01>;

		sysmmu@14860000 {
			reg = <0x00 0x14860000 0x3000>;
			qos = <0x0f>;
			interrupts = <0x00 0xc0 0x00 0x00 0xc1 0x00>;
			master_ip_list = <0x6d>;
			sysmmu,secure_reg = <0x14850000>;
			compatible = "samsung,exynos7420-sysmmu";
			clock-names = "aclk";
			sysmmu,handle_secure-irq;
			clocks = <0x11 0x44d>;
			sysmmu,v7tlb_property = <0x00 0x00 0x02 0x00 0x04 0x00 0x05 0x00>;
			samsung,power-domain = <0x0b>;
		};
	};

	interrupt-controller@104E1000 {
		reg = <0x00 0x104e1000 0x1000 0x00 0x104e2000 0x1000 0x00 0x104e4000 0x2000 0x00 0x104e6000 0x2000>;
		interrupts = <0x01 0x09 0xf04>;
		compatible = "arm,cortex-a15-gic\0arm,cortex-a9-gic";
		#interrupt-cells = <0x03>;
		#address-cells = <0x00>;
		phandle = <0x01>;
		interrupt-controller;
		linux,phandle = <0x01>;
	};

	input_booster {
		compatible = "input_booster";
		status = "okay";
		#address-cells = <0x01>;
		#size-cells = <0x00>;

		booster_key@9 {
			input_booster,label = "GAMEPAD";
			input_booster,phase_times = <0x00 0x00>;
			input_booster,kfc_freqs = <0x1506d0 0xca648>;
			input_booster,levels = <0x01 0x02>;
			input_booster,int_freqs = <0x00 0x00>;
			input_booster,type = <0x08>;
			input_booster,tail_times = <0x00 0x12c>;
			input_booster,cpu_freqs = <0x1506d0 0xca648>;
			input_booster,mif_freqs = <0x00 0x00>;
			input_booster,hmp_boost = <0x00 0x00>;
			input_booster,head_times = <0xc8 0x00>;
		};

		booster_key@8 {
			input_booster,label = "PEN & HOVER";
			input_booster,phase_times = <0x00 0x00>;
			input_booster,kfc_freqs = <0x137090 0xeadd0>;
			input_booster,levels = <0x01 0x02>;
			input_booster,int_freqs = <0x00 0x00>;
			input_booster,type = <0x07>;
			input_booster,tail_times = <0x00 0x12c>;
			input_booster,cpu_freqs = <0x137090 0xeadd0>;
			input_booster,mif_freqs = <0x00 0x00>;
			input_booster,hmp_boost = <0x00 0x00>;
			input_booster,head_times = <0xc8 0x00>;
		};

		booster_key@7 {
			input_booster,label = "MOUSE WHEEL";
			input_booster,phase_times = <0x00 0x00>;
			input_booster,kfc_freqs = <0x137090 0x00>;
			input_booster,levels = <0x01 0x02>;
			input_booster,int_freqs = <0x00 0x00>;
			input_booster,type = <0x06>;
			input_booster,tail_times = <0x00 0x00>;
			input_booster,cpu_freqs = <0x137090 0x00>;
			input_booster,mif_freqs = <0x00 0x00>;
			input_booster,hmp_boost = <0x00 0x00>;
			input_booster,head_times = <0xc8 0x00>;
		};

		booster_key@6 {
			input_booster,label = "MOUSE";
			input_booster,phase_times = <0x00 0x00>;
			input_booster,kfc_freqs = <0x137090 0xeadd0>;
			input_booster,levels = <0x01 0x02>;
			input_booster,int_freqs = <0x00 0x00>;
			input_booster,type = <0x05>;
			input_booster,tail_times = <0x00 0x12c>;
			input_booster,cpu_freqs = <0x137090 0xeadd0>;
			input_booster,mif_freqs = <0x00 0x00>;
			input_booster,hmp_boost = <0x00 0x00>;
			input_booster,head_times = <0xc8 0x00>;
		};

		booster_key@5 {
			input_booster,label = "KEYBOARD";
			input_booster,phase_times = <0x00 0x00>;
			input_booster,kfc_freqs = <0x137090 0x137090>;
			input_booster,levels = <0x01 0x02>;
			input_booster,int_freqs = <0x00 0x00>;
			input_booster,type = <0x04>;
			input_booster,tail_times = <0x00 0x00>;
			input_booster,cpu_freqs = <0x137090 0x137090>;
			input_booster,mif_freqs = <0x00 0x00>;
			input_booster,hmp_boost = <0x00 0x00>;
			input_booster,head_times = <0xc8 0xc8>;
		};

		booster_key@4 {
			input_booster,label = "MULTITOUCH";
			input_booster,phase_times = <0x00 0x00>;
			input_booster,kfc_freqs = <0x1506d0 0xfde80>;
			input_booster,levels = <0x01 0x02>;
			input_booster,int_freqs = <0x00 0x00>;
			input_booster,type = <0x03>;
			input_booster,tail_times = <0x00 0x1f4>;
			input_booster,cpu_freqs = <0x1506d0 0xfde80>;
			input_booster,mif_freqs = <0x00 0x00>;
			input_booster,hmp_boost = <0x00 0x00>;
			input_booster,head_times = <0x3e8 0x00>;
		};

		booster_key@3 {
			input_booster,label = "TOUCH";
			input_booster,phase_times = <0x00 0x00 0x00>;
			input_booster,kfc_freqs = <0x137090 0x137090 0xeadd0>;
			input_booster,levels = <0x01 0x02 0x03>;
			input_booster,int_freqs = <0x00 0x00 0x00>;
			input_booster,type = <0x02>;
			input_booster,tail_times = <0x00 0x00 0x12c>;
			input_booster,cpu_freqs = <0x137090 0x137090 0xeadd0>;
			input_booster,mif_freqs = <0x00 0x00 0x00>;
			input_booster,hmp_boost = <0x00 0x00 0x00>;
			input_booster,head_times = <0xc8 0xc8 0x00>;
		};

		booster_key@2 {
			input_booster,label = "TOUCHKEY";
			input_booster,phase_times = <0x00>;
			input_booster,kfc_freqs = <0x137090>;
			input_booster,levels = <0x01>;
			input_booster,int_freqs = <0x00>;
			input_booster,type = <0x01>;
			input_booster,tail_times = <0x12c>;
			input_booster,cpu_freqs = <0x137090>;
			input_booster,mif_freqs = <0x00>;
			input_booster,hmp_boost = <0x00>;
			input_booster,head_times = <0x00>;
		};

		booster_key@1 {
			input_booster,label = "KEY";
			input_booster,phase_times = <0x00>;
			input_booster,kfc_freqs = <0x137090>;
			input_booster,levels = <0x01>;
			input_booster,int_freqs = <0x00>;
			input_booster,type = <0x00>;
			input_booster,tail_times = <0x1f4>;
			input_booster,cpu_freqs = <0x137090>;
			input_booster,mif_freqs = <0x00>;
			input_booster,hmp_boost = <0x00>;
			input_booster,head_times = <0x1f4>;
		};
	};

	i2s@148B0000 {
		reg = <0x00 0x148b0000 0x100>;
		dmas = <0x3e 0x1f>;
		interrupts = <0x00 0x47 0x00>;
		compatible = "samsung,i2s-v5";
		clock-names = "iis\0i2s_opclk0\0i2s_opclk1";
		clocks = <0x11 0x2c8 0x11 0x2e5 0x11 0x2e5>;
		samsung,lpass-subip;
		status = "okay";
		samsung,supports-rstclr;
		phandle = <0x88>;
		samsung,supports-i2s-amp;
		samsung,i2s-str;
		dma-names = "rx";
		linux,phandle = <0x88>;
	};

	i2s@148A0000 {
		reg = <0x00 0x148a0000 0x100>;
		dmas = <0x3e 0x1d 0x3e 0x1e>;
		interrupts = <0x00 0x45 0x00>;
		samsung,supports-esa-dma;
		compatible = "samsung,i2s-v5";
		clock-names = "iis\0i2s_opclk0\0i2s_opclk1";
		clocks = <0x11 0x2c7 0x11 0x2e5 0x11 0x2e5>;
		samsung,lpass-subip;
		status = "okay";
		samsung,supports-secdai;
		samsung,supports-rstclr;
		phandle = <0x84>;
		samsung,i2s-str;
		dma-names = "tx\0rx";
		samsung,amixer = <0x04>;
		linux,phandle = <0x84>;

		i2s-sec {
			dmas = <0x3e 0x1c>;
			clock-names = "iis\0i2s_opclk0\0i2s_opclk1";
			clocks = <0x11 0x2c7 0x11 0x2e5 0x11 0x2e5>;
			dma-names = "tx-sec";
		};
	};

	i2c@20 {
		pinctrl-0 = <0x7c>;
		pinctrl-1 = <0x7c>;
		pinctrl-2 = <0x7d>;
		gpios = <0x7b 0x00 0x00 0x7b 0x01 0x00>;
		compatible = "i2c-gpio";
		#address-cells = <0x01>;
		i2c-gpio,delay-us = <0x05>;
		#size-cells = <0x00>;
		pinctrl-names = "default\0on_i2c\0off_i2c";

		touchkey@20 {
			reg = <0x20>;
			interrupts = <0x03 0x00 0x00>;
			pinctrl-0 = <0x7e>;
			pinctrl-1 = <0x7e>;
			pinctrl-2 = <0x7f>;
			coreriver,irq-gpio = <0x48 0x02 0x00>;
			compatible = "coreriver,tc300-keypad";
			coreriver,tsk_ic_num = <0x01>;
			coreriver,boot-on-ldo = "true";
			coreriver,sensing_ch_num = <0x04>;
			coreriver,i2c-gpio = "true";
			coreriver,regulator_ic = "vtouch_2.2v";
			pinctrl-names = "default\0on_irq\0off_irq";
			coreriver,use_bitmap = <0x01>;
			interrupt-parent = <0x48>;
			coreriver,scl-gpio = <0x7b 0x01 0x00>;
			coreriver,sda-gpio = <0x7b 0x00 0x00>;
			coreriver,fw_name = "coreriver/tc305k_j3y17.fw";
		};
	};

	i2c@138E0000 {
		reg = <0x00 0x138e0000 0x100>;
		interrupts = <0x00 0x1c6 0x00>;
		pinctrl-0 = <0x29>;
		compatible = "samsung,s3c2440-i2c";
		clock-names = "rate_i2c\0gate_i2c";
		clocks = <0x11 0x12d 0x11 0x12d>;
		status = "disabled";
		#address-cells = <0x01>;
		#size-cells = <0x00>;
		pinctrl-names = "default";
	};

	i2c@138D0000 {
		reg = <0x00 0x138d0000 0x100>;
		interrupts = <0x00 0x1c5 0x00>;
		pinctrl-0 = <0x24>;
		compatible = "samsung,s3c2440-i2c";
		clock-names = "rate_i2c\0gate_i2c";
		samsung,i2c-sda-delay = <0x64>;
		samsung,i2c-max-bus-freq = <0x61a80>;
		clocks = <0x11 0x12c 0x11 0x12c>;
		status = "okay";
		#address-cells = <0x01>;
		#size-cells = <0x00>;
		pinctrl-names = "default";

		gp2a@39 {
			reg = <0x39>;
			interrupts = <0x00 0x00 0x00>;
			gp2a,reg_prst = <0x38>;
			pinctrl-0 = <0x27>;
			compatible = "gp2a-i2c";
			gp2a,default_low_thd = <0x50>;
			gp2a,reg_ledctrl = <0x24>;
			gp2a,cancel_high_thd = <0x28>;
			gp2a,cancel_low_thd = <0x1e>;
			gp2a,vdd-supply = <0x28>;
			gp2a,irq-gpio = <0x17 0x00 0x00>;
			gp2a,vdd_always_on = <0x00>;
			gp2a,default_offset = <0x1e>;
			gp2a,default_high_thd = <0x82>;
			gp2a,reg_res_p = <0x20>;
			pinctrl-names = "default";
			gp2a,regulator_divided = <0x01>;
			interrupt-parent = <0x17>;
			gp2a,reg_intval = <0x03>;
		};

		stk3013@48 {
			reg = <0x48>;
			interrupts = <0x00 0x00 0x00>;
			stk,ps-cal-skip-adc = <0x0a>;
			pinctrl-0 = <0x27>;
			stk,ps-thd-h = <0x14>;
			stk,ps-thd-l = <0x0d>;
			stk,state-reg = <0x2c>;
			compatible = "stk,stk3013";
			stk,ledctrl-reg = <0xbf>;
			stk,wait-reg = <0x03>;
			stk,ps-cancel-thd-h = <0x0a>;
			stk,ps-cancel-thd-l = <0x07>;
			stk,vdd_always_on = <0x00>;
			stk,irq-gpio = <0x17 0x00 0x00>;
			stk,regulator_divided = <0x01>;
			stk,ps-cal-fail-adc = <0x17>;
			stk,psctrl-reg = <0x71>;
			stk,vdd-supply = <0x28>;
			pinctrl-names = "default";
			stk,ps-default-offset = <0x03>;
			interrupt-parent = <0x17>;
		};

		k2hh-i2c@1D {
			reg = <0x1d>;
			interrupts = <0x02 0x00 0x00>;
			pinctrl-0 = <0x25>;
			k2hh,poll_interval = <0x64>;
			compatible = "k2hh-i2c";
			k2hh,vio-supply = <0x26>;
			k2hh,min_interval = <0x02>;
			k2hh,negate_x = <0x00>;
			k2hh,negate_y = <0x00>;
			k2hh,negate_z = <0x01>;
			k2hh,axis_map_x = <0x00>;
			k2hh,axis_map_y = <0x01>;
			k2hh,axis_map_z = <0x02>;
			pinctrl-names = "default";
			k2hh,irq_gpio = <0x18 0x02 0x00>;
			interrupt-parent = <0x18>;
		};
	};

	i2c@13890000 {
		reg = <0x00 0x13890000 0x100>;
		interrupts = <0x00 0x1ae 0x00>;
		pinctrl-0 = <0x1d>;
		compatible = "samsung,s3c2440-i2c";
		clock-names = "rate_i2c\0gate_i2c";
		samsung,i2c-max-bus-freq = <0x61a80>;
		clocks = <0x11 0x137 0x11 0x137>;
		status = "okay";
		#address-cells = <0x01>;
		#size-cells = <0x00>;
		pinctrl-names = "default";

		isl98611@29 {
			reg = <0x29>;
			compatible = "i2c,isl98611";
		};
	};

	i2c@13880000 {
		reg = <0x00 0x13880000 0x100>;
		interrupts = <0x00 0x1ad 0x00>;
		pinctrl-0 = <0x1b>;
		compatible = "samsung,s3c2440-i2c";
		clock-names = "rate_i2c\0gate_i2c";
		clocks = <0x11 0x138 0x11 0x138>;
		status = "okay";
		#address-cells = <0x01>;
		samsung,i2c-clk-logging;
		#size-cells = <0x00>;
		pinctrl-names = "default";

		muic-universal@14 {
			reg = <0x14>;
			muic-universal,irq-gpio = <0x17 0x01 0x00>;
			pinctrl-0 = <0x1c>;
			compatible = "muic-universal";
			muic-universal,chip_name = "sm,sm5504";
			status = "okay";
			pinctrl-names = "default";
		};
	};

	i2c@13840000 {
		reg = <0x00 0x13840000 0x100>;
		interrupts = <0x00 0x1a9 0x00>;
		pinctrl-0 = <0x1e>;
		compatible = "samsung,s3c2440-i2c";
		clock-names = "rate_i2c\0gate_i2c";
		samsung,i2c-max-bus-freq = <0x61a80>;
		clocks = <0x11 0x12e 0x11 0x12e>;
		status = "okay";
		#address-cells = <0x01>;
		#size-cells = <0x00>;
		pinctrl-names = "default";

		touchscreen@4b {
			reg = <0x4b>;
			synaptics,max_coords = <0x2d0 0x500>;
			pinctrl-0 = <0x1f>;
			pinctrl-1 = <0x20>;
			pinctrl-2 = <0x21>;
			compatible = "synaptics,rmi4";
			synaptics,firmware_name = "tsp_synaptics/td4100_j3y17.fw";
			synaptics,num_lines = <0x1d 0x10>;
			synaptics,irq_gpio = <0x22 0x02 0x00>;
			synaptics,irq_type = <0x2008>;
			synaptics,firmware_name_bl = "tsp_synaptics/td4100_j3y17_recovery.fw";
			synaptics,project_name = "J3y\0J330";
			synaptics,reset-delay-ms = <0x96>;
			synaptics,ub-i2c-addr = <0x2c>;
			pinctrl-names = "default\0on_state\0off_state";
		};
	};

	i2c@13830000 {
		reg = <0x00 0x13830000 0x100>;
		interrupts = <0x00 0x1a8 0x00>;
		pinctrl-0 = <0x23>;
		compatible = "samsung,s3c2440-i2c";
		clock-names = "rate_i2c\0gate_i2c";
		clocks = <0x11 0x136 0x11 0x136>;
		status = "disabled";
		#address-cells = <0x01>;
		#size-cells = <0x00>;
		pinctrl-names = "default";
	};

	hsi2c@13960000 {
		reg = <0x00 0x13960000 0x1000>;
		interrupts = <0x00 0x1ca 0x00>;
		pinctrl-0 = <0x2c>;
		compatible = "samsung,exynos5-hsi2c";
		clock-names = "rate_hsi2c\0gate_hsi2c";
		clocks = <0x11 0x14d 0x11 0x14d>;
		samsung,scl-clk-stretching;
		status = "disabled";
		samsung,check-transdone-int;
		#address-cells = <0x01>;
		#size-cells = <0x00>;
		gpio_scl = <0x2b 0x02 0x01>;
		gpio_sda = <0x2b 0x03 0x01>;
		pinctrl-names = "default";
	};

	hsi2c@13950000 {
		reg = <0x00 0x13950000 0x1000>;
		interrupts = <0x00 0x1c9 0x00>;
		pinctrl-0 = <0x2a>;
		gpios = <0x2b 0x01 0x00 0x2b 0x00 0x00>;
		compatible = "samsung,exynos5-hsi2c";
		clock-names = "rate_hsi2c\0gate_hsi2c";
		clock-frequency = <0x61a80>;
		clocks = <0x11 0x14c 0x11 0x14c>;
		samsung,scl-clk-stretching;
		status = "okay";
		samsung,check-transdone-int;
		#address-cells = <0x01>;
		#size-cells = <0x00>;
		gpio_scl = <0x2b 0x00 0x01>;
		gpio_sda = <0x2b 0x01 0x01>;
		pinctrl-names = "default";
	};

	hsi2c@13940000 {
		reg = <0x00 0x13940000 0x1000>;
		interrupts = <0x00 0x1d0 0x00>;
		pinctrl-0 = <0x42>;
		compatible = "samsung,exynos5-hsi2c";
		clock-names = "rate_hsi2c\0gate_hsi2c";
		clocks = <0x11 0x160 0x11 0x160>;
		samsung,scl-clk-stretching;
		status = "disabled";
		samsung,check-transdone-int;
		#address-cells = <0x01>;
		#size-cells = <0x00>;
		gpio_scl = <0x18 0x07 0x01>;
		gpio_sda = <0x18 0x06 0x01>;
		pinctrl-names = "default";
	};

	hsi2c@13930000 {
		reg = <0x00 0x13930000 0x1000>;
		interrupts = <0x00 0x1cf 0x00>;
		pinctrl-0 = <0x41>;
		compatible = "samsung,exynos5-hsi2c";
		clock-names = "rate_hsi2c\0gate_hsi2c";
		clocks = <0x11 0x160 0x11 0x160>;
		samsung,scl-clk-stretching;
		status = "disabled";
		samsung,check-transdone-int;
		#address-cells = <0x01>;
		#size-cells = <0x00>;
		gpio_scl = <0x18 0x05 0x01>;
		gpio_sda = <0x18 0x04 0x01>;
		pinctrl-names = "default";
	};

	hsi2c@13920000 {
		reg = <0x00 0x13920000 0x1000>;
		interrupts = <0x00 0x1cc 0x00>;
		pinctrl-0 = <0x40>;
		compatible = "samsung,exynos5-hsi2c";
		clock-names = "rate_hsi2c\0gate_hsi2c";
		clocks = <0x11 0x15f 0x11 0x15f>;
		samsung,scl-clk-stretching;
		status = "disabled";
		samsung,check-transdone-int;
		#address-cells = <0x01>;
		#size-cells = <0x00>;
		gpio_scl = <0x18 0x02 0x01>;
		gpio_sda = <0x18 0x01 0x01>;
		pinctrl-names = "default";
	};

	hsi2c@13910000 {
		reg = <0x00 0x13910000 0x1000>;
		interrupts = <0x00 0x1cb 0x00>;
		pinctrl-0 = <0x3f>;
		compatible = "samsung,exynos5-hsi2c";
		clock-names = "rate_hsi2c\0gate_hsi2c";
		clocks = <0x11 0x15f 0x11 0x15f>;
		samsung,scl-clk-stretching;
		status = "disabled";
		samsung,check-transdone-int;
		#address-cells = <0x01>;
		#size-cells = <0x00>;
		gpio_scl = <0x18 0x00 0x01>;
		gpio_sda = <0x17 0x07 0x01>;
		pinctrl-names = "default";
	};

	hsi2c@138C0000 {
		reg = <0x00 0x138c0000 0x1000>;
		interrupts = <0x00 0x1c3 0x00>;
		pinctrl-0 = <0x2f>;
		pinctrl-1 = <0x2f>;
		gpios = <0x2e 0x02 0x00 0x2e 0x03 0x00>;
		compatible = "samsung,exynos5-hsi2c";
		clock-names = "rate_hsi2c\0gate_hsi2c";
		clock-frequency = <0x61a80>;
		clocks = <0x11 0x140 0x11 0x140>;
		samsung,scl-clk-stretching;
		status = "okay";
		samsung,check-transdone-int;
		#address-cells = <0x01>;
		#size-cells = <0x00>;
		gpio_scl = <0x2e 0x03 0x01>;
		gpio_sda = <0x2e 0x02 0x01>;
		pinctrl-names = "default\0on_i2c";

		fimc-is-actuator@0C {
			id = <0x00>;
			reg = <0x0c>;
			compatible = "samsung,exynos5-fimc-is-actuator-dw9807";
		};

		rear_eeprom@58 {
			reg = <0x58>;
			compatible = "samsung,rear-eeprom-i2c";
		};
	};

	hsi2c@138B0000 {
		reg = <0x00 0x138b0000 0x1000>;
		interrupts = <0x00 0x1c2 0x00>;
		pinctrl-0 = <0x30>;
		compatible = "samsung,exynos5-hsi2c";
		clock-names = "rate_hsi2c\0gate_hsi2c";
		clock-frequency = <0x61a80>;
		clocks = <0x11 0x142 0x11 0x142>;
		samsung,scl-clk-stretching;
		status = "okay";
		samsung,check-transdone-int;
		#address-cells = <0x01>;
		#size-cells = <0x00>;
		gpio_scl = <0x31 0x01 0x01>;
		gpio_sda = <0x31 0x00 0x01>;
		pinctrl-names = "default";

		sec-nfc@27 {
			reg = <0x27>;
			interrupts = <0x06 0x00 0x00>;
			sec-nfc,check_nfc = <0x18 0x05 0x00>;
			pinctrl-0 = <0x34 0x35 0x36 0x37 0x38 0x39>;
			clkctrl-reg = <0x11c8600c>;
			compatible = "sec-nfc";
			sec-nfc,nfc_pd = <0x32 0x02 0x02>;
			sec-nfc,firm-gpio = <0x2b 0x02 0x01>;
			sec-nfc,irq-gpio = <0x18 0x07 0x00>;
			sec-nfc,nfc_clkreq = <0x32 0x03 0x02>;
			sec-nfc,pvdd_en = <0x33 0x01 0x01>;
			pinctrl-names = "default";
			interrupt-parent = <0x18>;
		};
	};

	hsi2c@138A0000 {
		reg = <0x00 0x138a0000 0x1000>;
		interrupts = <0x00 0x1c1 0x00>;
		pinctrl-0 = <0x2d>;
		pinctrl-1 = <0x2d>;
		gpios = <0x2e 0x00 0x00 0x2e 0x01 0x00>;
		compatible = "samsung,exynos5-hsi2c";
		clock-names = "rate_hsi2c\0gate_hsi2c";
		clock-frequency = <0x61a80>;
		clocks = <0x11 0x141 0x11 0x141>;
		samsung,scl-clk-stretching;
		status = "okay";
		samsung,check-transdone-int;
		#address-cells = <0x01>;
		#size-cells = <0x00>;
		gpio_scl = <0x2e 0x01 0x01>;
		gpio_sda = <0x2e 0x00 0x01>;
		pinctrl-names = "default\0on_i2c";

		fimc-is-5e3@10 {
			id = <0x01>;
			reg = <0x10>;
			compatible = "samsung,exynos5-fimc-is-cis-5e3";
			setfile = "default";
			sensor_f_number = <0x04>;
		};

		fimc-is-3l2@2D {
			id = <0x00>;
			reg = <0x2d>;
			compatible = "samsung,exynos5-fimc-is-cis-3l2";
			setfile = "default";
			sensor_f_number = <0x02>;
		};
	};

	hs_tune {
		otg = <0x02 0x02>;
		compdis = <0x03 0x03>;
		enable_user_imp = <0x00 0x00>;
		rx_sqrx = <0x05 0x05>;
		tx_pre_emp = <0x00 0x00>;
		tx_fsls = <0x03 0x03>;
		tx_hsxv = <0x00 0x00>;
		tx_rise = <0x01 0x01>;
		tx_vref = <0x03 0x03>;
		status = "okay";
		is_phyclock = <0x01>;
		tx_res = <0x02 0x02>;
		phandle = <0x6f>;
		tx_pre_emp_puls = <0x00 0x00>;
		linux,phandle = <0x6f>;
	};

	gpio_keys {
		pinctrl-0 = <0x78 0x79 0x7a>;
		compatible = "gpio-keys";
		#address-cells = <0x01>;
		#size-cells = <0x00>;
		pinctrl-names = "default";

		button@3 {
			interrupts = <0x03 0x00 0x00>;
			gpios = <0x18 0x03 0x0f>;
			label = "gpio-keys: KEY_VOLUMEDOWN";
			linux,code = <0x72>;
			interrupt-parent = <0x18>;
		};

		button@2 {
			interrupts = <0x04 0x00 0x00>;
			gpios = <0x48 0x04 0x0f>;
			label = "gpio-keys: KEY_HOME";
			gpio-key,wakeup = <0x01>;
			linux,code = <0xac>;
			interrupt-parent = <0x48>;
		};

		button@1 {
			interrupts = <0x07 0x00 0x00>;
			gpios = <0x48 0x07 0x0f>;
			label = "gpio-keys: KEY_VOLUMEUP";
			linux,code = <0x73>;
			interrupt-parent = <0x48>;
		};
	};

	gnss_pdata {
		interrupts = <0x00 0x13 0x00 0x00 0x1de 0x00 0x00 0x1dd 0x00>;
		mbx,int_ap2gnss_req_fault_info = <0x01>;
		compatible = "samsung,gnss_shdmem_if";
		mbx,irq_gnss2ap_ipc_msg = <0x02>;
		shmem,ipc_reg_cnt = <0x20>;
		mbx,int_ap2gnss_ack_wake_clr = <0x04>;
		mbx,int_ap2gnss_ack_wake_set = <0x03>;
		shmem,device_node_name = "gnss_ipc";
		reg_rx_ipc_msg = <0x01 0x05>;
		reg_rx_head = <0x01 0x03>;
		reg_rx_tail = <0x01 0x02>;
		fault_info = <0x01 0x100000 0x100000>;
		mbx,reg_bcmd_ctrl = <0x00 0x01 0x02 0x03>;
		reg_tx_head = <0x01 0x01>;
		reg_tx_tail = <0x01 0x00>;
		mbx,int_ap2gnss_bcmd = <0x00>;
		status = "okay";
		shmem,ipc_size = <0x80000>;
		shmem,name = "KEPLER";
		reg_tx_ipc_msg = <0x01 0x04>;
		mbx,irq_gnss2ap_bcmd = <0x00>;
		mbx,int_ap2gnss_ipc_msg = <0x02>;
		mbx,irq_gnss2ap_req_wake_clr = <0x04>;
		mbx,irq_gnss2ap_rsp_fault_info = <0x01>;
		shmem,ipc_offset = <0x180000>;
	};

	fm_dummy {
		compatible = "samsung,fm_dummy";
		status = "okay";
		phandle = <0x87>;
		linux,phandle = <0x87>;
	};

	fm@14840000 {
		reg = <0x00 0x14840000 0x2000 0x00 0x11c80000 0x1000 0x00 0x10580000 0x100 0x00 0x148d0000 0x500 0x00 0x10460000 0x3000 0x00 0x13730000 0x2000 0x00 0x14880000 0x100>;
		interrupts = <0x00 0xc3 0x00>;
		pinctrl-0 = <0x75>;
		compatible = "samsung,exynos7570-fm";
		clock-names = "oscclk_fm_52m_div";
		sw_mute_weak = <0x01>;
		clocks = <0x11 0x2e7>;
		elna_gpio = <0x74 0x00 0x01>;
		status = "okay";
		fm_iclk_aux = <0x00>;
		samsung,syscon-phandle = <0x0f>;
		samsung,power-domain = <0x73>;
		pinctrl-names = "default";
	};

	fixedregulator@1 {
		gpio = <0x48 0x03 0x01>;
		regulator-name = "vmmc";
		compatible = "regulator-fixed";
		enable-active-high;
		regulator-min-microvolt = <0x2ab980>;
		regulator-max-microvolt = <0x2ab980>;
		regulator-initial-mode = <0x00>;
		regulator-boot-on;
	};

	fixed-rate-clocks {

		oscclk {
			compatible = "samsung,exynos7570-oscclk";
			clock-frequency = <0x18cba80>;
		};
	};

	firmware {

		android {
			compatible = "android,firmware";

			fstab {
				compatible = "android,fstab";

				system {
					dev = "/dev/block/platform/13540000.dwmmc0/by-name/SYSTEM";
					type = "ext4";
					mnt_flags = "ro";
					fsmgr_flags = <0x77616974 0x00 0x00>;
					compatible = "android,system";
				};
			};
		};
	};

	fips-fmp {
		compatible = "samsung,exynos-fips-fmp";
	};

	fimc_is_sensor1@14420000 {
		id = <0x01>;
		reg = <0x00 0x14420000 0x10000 0x00 0x14410000 0x10000>;
		phys = <0x72 0x00>;
		interrupts = <0x00 0x90 0x00 0x00 0x89 0x00>;
		compatible = "samsung,exynos5-fimc-is-sensor";
		clock-names = "mif_isp_sensor0";
		scenario = <0x00>;
		phy-names = "csis_dphy";
		clocks = <0x11 0x2b>;
		csi_ch = <0x00>;
		is_bns = <0x01>;
		status = "okay";
		#pb-id-cells = <0x00>;
		flite_ch = <0x00>;
		phandle = <0x6c>;
		samsung,power-domain = <0x0c>;
		linux,phandle = <0x6c>;
	};

	fimc_is_sensor0@14420000 {
		id = <0x00>;
		reg = <0x00 0x14420000 0x10000 0x00 0x14410000 0x10000>;
		phys = <0x72 0x01>;
		interrupts = <0x00 0x90 0x00 0x00 0x89 0x00>;
		compatible = "samsung,exynos5-fimc-is-sensor";
		clock-names = "mif_isp_sensor0";
		scenario = <0x00>;
		phy-names = "csis_dphy";
		clocks = <0x11 0x2b>;
		csi_ch = <0x00>;
		is_bns = <0x01>;
		status = "okay";
		#pb-id-cells = <0x00>;
		flite_ch = <0x00>;
		phandle = <0x6b>;
		samsung,power-domain = <0x0c>;
		linux,phandle = <0x6b>;
	};

	fimc_is@14400000 {
		reg = <0x00 0x14400000 0xc400 0x00 0x14430000 0x2000 0x00 0x14440000 0x10000 0x00 0x14450000 0x10000 0x00 0x14480000 0xc400 0x00 0x12c00000 0x2000>;
		interrupts = <0x00 0x8b 0x00 0x00 0x8c 0x00 0x00 0x8d 0x00 0x00 0x8e 0x00 0x00 0x92 0x00 0x00 0x190 0x00>;
		compatible = "samsung,exynos5-fimc-is";
		clock-names = "oscclk\0isp_ppmu\0isp_bts\0isp_cam\0isp_vra\0umux_isp_clkphy_isp_s_rxbyteclkhs0_s4_user\0gate_mscl\0mif_isp_sensor0";
		clocks = <0x11 0x01 0x11 0x321 0x11 0x322 0x11 0x323 0x11 0x324 0x11 0x32a 0x11 0x262 0x11 0x2b>;
		status = "ok";
		#pb-id-cells = <0x00>;
		phandle = <0x6a>;
		samsung,power-domain = <0x0c>;
		linux,phandle = <0x6a>;

		vender {
			rear_sensor_id = <0x08>;
			use_module_check;
			front_sensor_id = <0x11>;
			total_camera_num = <0x02>;

			camera_info1 {
				isp = <0x00>;
				ois = <0x00>;
				companion = <0x00>;
				cal_memory = <0x03>;
				read_version = <0x00>;
				upgrade = <0x00>;
				core_voltage = <0x00>;
			};

			camera_info0 {
				isp = <0x00>;
				ois = <0x00>;
				companion = <0x00>;
				cal_memory = <0x02>;
				read_version = <0x00>;
				upgrade = <0x00>;
				core_voltage = <0x00>;
			};
		};

		fimc_is_dvfs {

			table1 {
				desc = "HAL3 version";
				rear_video_capture_cam = <0x87410>;
				rear_video_capture_i2c = <0x00>;
				rear_video_capture_int = <0x72038>;
				rear_video_capture_mif = <0xcaa30>;
				rear_preview_cam = <0x87410>;
				rear_preview_i2c = <0x00>;
				rear_preview_int = <0x72038>;
				rear_preview_mif = <0xcaa30>;
				default_cam = <0x87410>;
				default_i2c = <0x00>;
				default_int = <0x72038>;
				default_mif = <0xcaa30>;
				front_preview_cam = <0x6c660>;
				front_preview_i2c = <0x00>;
				front_preview_int = <0x72038>;
				front_preview_mif = <0xcaa30>;
				front_vt1_cam = <0x6c660>;
				front_vt1_i2c = <0x00>;
				front_vt1_int = <0x72038>;
				front_vt1_mif = <0xcaa30>;
				front_vt2_cam = <0x6c660>;
				front_vt2_i2c = <0x00>;
				front_vt2_int = <0x72038>;
				front_vt2_mif = <0xcaa30>;
				max_cam = <0xa2990>;
				max_i2c = <0x00>;
				max_int = <0x72038>;
				max_mif = <0xcaa30>;
				preview_high_speed_fps_cam = <0x87410>;
				preview_high_speed_fps_i2c = <0x00>;
				preview_high_speed_fps_int = <0x72038>;
				preview_high_speed_fps_mif = <0xcaa30>;
				rear_capture_cam = <0x87410>;
				rear_capture_i2c = <0x00>;
				rear_capture_int = <0x72038>;
				rear_capture_mif = <0xcaa30>;
				front_capture_cam = <0x6c660>;
				front_capture_i2c = <0x00>;
				front_capture_int = <0x72038>;
				front_capture_mif = <0xcaa30>;
				rear_video_cam = <0x87410>;
				rear_video_i2c = <0x00>;
				rear_video_int = <0x72038>;
				rear_video_mif = <0xcaa30>;
				video_high_speed_120fps_cam = <0x87410>;
				video_high_speed_120fps_i2c = <0x00>;
				video_high_speed_120fps_int = <0x72038>;
				video_high_speed_120fps_mif = <0xcaa30>;
				front_video_cam = <0x6c660>;
				front_video_i2c = <0x00>;
				front_video_int = <0x72038>;
				front_video_mif = <0xcaa30>;
				front_video_capture_cam = <0x6c660>;
				front_video_capture_i2c = <0x00>;
				front_video_capture_int = <0x72038>;
				front_video_capture_mif = <0xcaa30>;
				video_high_speed_60fps_cam = <0x87410>;
				video_high_speed_60fps_i2c = <0x00>;
				video_high_speed_60fps_int = <0x72038>;
				video_high_speed_60fps_mif = <0xcaa30>;
			};

			table0 {
				desc = "HAL1 version";
				rear_video_capture_cam = <0x87410>;
				rear_video_capture_i2c = <0x00>;
				rear_video_capture_int = <0x72038>;
				rear_video_capture_mif = <0xcaa30>;
				rear_preview_cam = <0x87410>;
				rear_preview_i2c = <0x00>;
				rear_preview_int = <0x72038>;
				rear_preview_mif = <0xcaa30>;
				default_cam = <0x87410>;
				default_i2c = <0x00>;
				default_int = <0x72038>;
				default_mif = <0xcaa30>;
				front_preview_cam = <0x6c660>;
				front_preview_i2c = <0x00>;
				front_preview_int = <0x72038>;
				front_preview_mif = <0xcaa30>;
				front_vt1_cam = <0x6c660>;
				front_vt1_i2c = <0x00>;
				front_vt1_int = <0x72038>;
				front_vt1_mif = <0xcaa30>;
				front_vt2_cam = <0x6c660>;
				front_vt2_i2c = <0x00>;
				front_vt2_int = <0x72038>;
				front_vt2_mif = <0xcaa30>;
				max_cam = <0xa2990>;
				max_i2c = <0x00>;
				max_int = <0x72038>;
				max_mif = <0xcaa30>;
				preview_high_speed_fps_cam = <0x87410>;
				preview_high_speed_fps_i2c = <0x00>;
				preview_high_speed_fps_int = <0x72038>;
				preview_high_speed_fps_mif = <0xcaa30>;
				rear_capture_cam = <0x87410>;
				rear_capture_i2c = <0x00>;
				rear_capture_int = <0x72038>;
				rear_capture_mif = <0xcaa30>;
				front_capture_cam = <0x6c660>;
				front_capture_i2c = <0x00>;
				front_capture_int = <0x72038>;
				front_capture_mif = <0xcaa30>;
				rear_video_cam = <0x87410>;
				rear_video_i2c = <0x00>;
				rear_video_int = <0x72038>;
				rear_video_mif = <0xcaa30>;
				video_high_speed_120fps_cam = <0x87410>;
				video_high_speed_120fps_i2c = <0x00>;
				video_high_speed_120fps_int = <0x72038>;
				video_high_speed_120fps_mif = <0xcaa30>;
				front_video_cam = <0x6c660>;
				front_video_i2c = <0x00>;
				front_video_int = <0x72038>;
				front_video_mif = <0xcaa30>;
				front_video_capture_cam = <0x6c660>;
				front_video_capture_i2c = <0x00>;
				front_video_capture_int = <0x72038>;
				front_video_capture_mif = <0xcaa30>;
				video_high_speed_60fps_cam = <0x87410>;
				video_high_speed_60fps_i2c = <0x00>;
				video_high_speed_60fps_int = <0x72038>;
				video_high_speed_60fps_mif = <0xcaa30>;
			};
		};
	};

	fimc-is_sensor_5e3@10 {
		id = <0x01>;
		pinctrl-0;
		pinctrl-1 = <0x80>;
		pinctrl-2 = <0x82>;
		compatible = "samsung,sensor-module-5e3";
		sensor_i2c_ch = <0x00>;
		gpio_reset = <0x74 0x06 0x01>;
		mclk_ch = <0x00>;
		position = <0x01>;
		status = "okay";
		sensor_i2c_addr = <0x10>;
		pinctrl-names = "pin0\0pin1\0pin2";
	};

	fimc-is_sensor_3l2@2D {
		id = <0x00>;
		pinctrl-0;
		pinctrl-1 = <0x80 0x81>;
		pinctrl-2 = <0x82 0x81>;
		compatible = "samsung,sensor-module-3l2";
		sensor_i2c_ch = <0x00>;
		gpio_reset = <0x74 0x01 0x01>;
		mclk_ch = <0x00>;
		position = <0x00>;
		status = "okay";
		sensor_i2c_addr = <0x2d>;
		pinctrl-names = "pin0\0pin1\0pin2";

		flash {
			product_name = <0x0d>;
			flash_first_gpio = <0x02>;
			flash_second_gpio = <0x01>;
		};

		af {
			i2c_addr = <0x0c>;
			product_name = <0x0d>;
			i2c_ch = <0x01>;
		};
	};

	exynos_rgt {
		compatible = "samsung,exynos-rgt";
	};

	exynos-powermode {
		compatible = "exynos,powermode";
		wakeup_mask = <0x400f91e1 0x00 0x00 0x00 0x00 0x00 0x00 0x00 0x400ffffe>;
		cpd_residency = <0xbb8>;
		wakeup_mask2 = <0x00 0x00 0x00 0x00 0x00 0x00 0x00 0x00 0xffff00ff>;
		wakeup_mask3 = <0x00 0x00 0x00 0x00 0x00 0x00 0x00 0x00 0xffff00ff>;
		idle-ip = "136c0000.pwm\010550000.adc\010510000.hsi2c\013950000.hsi2c\013960000.hsi2c\0138a0000.hsi2c\0138b0000.hsi2c\0138c0000.hsi2c\0138f0000.hsi2c\013870000.i2c\013880000.i2c\013890000.i2c\013840000.i2c\013830000.i2c\0138d0000.i2c\0138e0000.i2c\013850000.i2c\013860000.i2c\013540000.dwmmc0\013560000.dwmmc2\013600000.usb\0100c0000.spi\013900000.spi\013910000.spi\013920000.spi\013930000.spi\010500000.mailbox-cp\010570000.mailbox-gnss\014830000.decon_fb\0pd-g3d\0pd-isp\0pd-mfcmscl\0148f0000.lpass";
		sicd_enabled = <0x00>;
		sicd_residency = <0xbb8>;

		idle_ip_mask {

			SYS_SICD {
				mode-index = <0x00>;
				ref-idle-ip = <0x00 0x01 0x02 0x03 0x04 0x05 0x06 0x07 0x08 0x09 0x0a 0x0b 0x0c 0x0d 0x0e 0x0f 0x10 0x11 0x12 0x13 0x14 0x15 0x16 0x17 0x18 0x19 0x1a 0x1b 0x1c 0x1d 0x1e 0x1f 0x20>;
			};
		};
	};

	exynos-pmu {
		compatible = "samsung,exynos-pmu";
		samsung,syscon-phandle = <0x0f>;
	};

	exynos-pm {
		reg = <0x00 0x139f0000 0x1000 0x00 0x104e1200 0x100>;
		reg-names = "gpio_alive_base\0gicd_ispendrn_base";
		compatible = "samsung,exynos-pm";
		cp_call_mode_idx = <0x04>;
		suspend_psci_idx = <0x83>;
		cp_call_psci_idx = <0x84>;
		num-gic = <0x10>;
		num-eint = <0x18>;
		suspend_mode_idx = <0x08>;
	};

	ect {
		parameter_address = <0x7e0fa000>;
		parameter_size = <0x6000>;
	};

	eax {
		compatible = "samsung,exynos-amixer";
		status = "ok";
		phandle = <0x89>;
		linux,phandle = <0x89>;
	};

	dwmmc2@13560000 {
		reg = <0x00 0x13560000 0x2000>;
		interrupts = <0x00 0xf7 0x00>;
		pinctrl-0 = <0x58 0x59 0x5a 0x5b 0x5c 0x5d>;
		pinctrl-1 = <0x5e>;
		pinctrl-2 = <0x5f>;
		pinctrl-3 = <0x60>;
		pinctrl-4 = <0x61>;
		samsung,dw-mshc-ciu-div = <0x03>;
		compatible = "samsung,exynos-dw-mshc";
		clock-names = "biu\0ciu\0ciu_gate";
		supports-4bit;
		num-slots = <0x01>;
		clock-frequency = <0x29b92700>;
		skip-init-mmc-scan;
		switch_transfer;
		data-timeout = <0xc8>;
		supports-highspeed;
		clk-drive-number = <0x04>;
		card-detect-gpio;
		hto-timeout = <0x50>;
		ignore-phase = <0x80>;
		desc-size = <0x04>;
		samsung,dw-mshc-sdr104-timing = <0x03 0x00 0x03 0x00>;
		clocks = <0x11 0x202 0x11 0x204 0x11 0x1f>;
		samsung,dw-mshc-sdr50-timing = <0x03 0x00 0x04 0x02>;
		fifo-depth = <0x40>;
		card-detect = <0x48 0x01 0x0f>;
		ciu_clkin = <0x19 0x2b 0x2b 0x19 0x2b 0x57 0xaf 0x2b 0x2b>;
		card-init-hwacg-ctrl;
		sec-sd-slot-type = <0x02>;
		use-fine-tuning;
		bypass-smu;
		status = "okay";
		card-detect-delay = <0xc8>;
		supports-cmd23;
		supports-erase;
		num-ref-clks = <0x09>;
		sd-uhs-sdr104;
		#address-cells = <0x01>;
		bypass-for-allpass;
		samsung,dw-mshc-sdr-timing = <0x03 0x00 0x02 0x00>;
		sd-uhs-sdr50;
		clock-gate;
		only_once_tune;
		#size-cells = <0x00>;
		samsung,dw-mshc-ddr-timing = <0x03 0x00 0x02 0x01>;
		pinctrl-names = "default\0fast-slew-rate-1x\0fast-slew-rate-2x\0fast-slew-rate-3x\0fast-slew-rate-4x";

		slot@0 {
			reg = <0x00>;
			bus-width = <0x04>;
			disable-wp;
		};
	};

	dwmmc0@13540000 {
		reg = <0x00 0x13540000 0x2000>;
		interrupts = <0x00 0xf5 0x00>;
		pinctrl-0 = <0x4e 0x4f 0x50 0x51 0x52 0x53>;
		pinctrl-1 = <0x54>;
		pinctrl-2 = <0x55>;
		pinctrl-3 = <0x56>;
		pinctrl-4 = <0x57>;
		samsung,dw-mshc-txdt-crc-timer-initval = <0x38>;
		mmc_pwr_shut_down;
		samsung,dw-mshc-ciu-div = <0x03>;
		mmc-hs200-1_8v;
		compatible = "samsung,exynos-dw-mshc";
		clock-names = "biu\0ciu\0ciu_gate";
		supports-8bit;
		num-slots = <0x01>;
		clock-frequency = <0x29b92700>;
		data-timeout = <0xc8>;
		supports-highspeed;
		mmc-hs400-1_8v;
		enable-ulp-mode;
		clk-drive-number = <0x04>;
		hto-timeout = <0x50>;
		desc-size = <0x04>;
		clocks = <0x11 0x201 0x11 0x203 0x11 0x1e>;
		fifo-depth = <0x40>;
		supports-hs400-enhanced-strobe;
		non-removable;
		ciu_clkin = <0x19 0x2b 0x2b 0x19 0x2b 0x57 0xaf 0x2b 0x2b 0xaf 0xaf 0xaf>;
		card-init-hwacg-ctrl;
		broken-card-detect;
		samsung,dw-mshc-hs200-timing = <0x03 0x00 0x03 0x00>;
		status = "okay";
		samsung,dw-mshc-ddr200-timing = <0x01 0x00 0x04 0x00>;
		card-detect-delay = <0xc8>;
		use-smu;
		samsung,dw-mshc-txdt-crc-timer-fastlimit = <0x34>;
		samsung,dw-mshc-ddr200-delay-line = <0x60>;
		supports-cmd23;
		supports-erase;
		pm-skip-mmc-resume-init;
		num-ref-clks = <0x0c>;
		#address-cells = <0x01>;
		samsung,dw-mshc-sdr-timing = <0x03 0x00 0x02 0x00>;
		clock-gate;
		samsung,dw-mshc-ddr200-ulp-timing = <0x03 0x00 0x03 0x00>;
		fixed_voltage;
		mmc-ddr-1_8v;
		#size-cells = <0x00>;
		samsung,dw-mshc-ddr-timing = <0x03 0x00 0x04 0x02>;
		pinctrl-names = "default\0fast-slew-rate-1x\0fast-slew-rate-2x\0fast-slew-rate-3x\0fast-slew-rate-4x";

		slot@0 {
			reg = <0x00>;
			bus-width = <0x08>;
		};
	};

	dummy-i2s {
		compatible = "samsung,dummy-i2s";
		status = "okay";
	};

	dummy-codec {
		compatible = "samsung,dummy-codec";
		status = "okay";
		phandle = <0x8a>;
		linux,phandle = <0x8a>;
	};

	dsim@14800000 {
		reg = <0x00 0x14800000 0x100>;
		phys = <0x63 0x00>;
		interrupts = <0x00 0xcf 0x00>;
		compatible = "samsung,exynos8-mipi-dsi";
		clock-names = "dsim_pclk\0dphy_escclk\0dphy_byteclk";
		phy-names = "dsim_dphy";
		data_lane_cnt = <0x04>;
		clocks = <0x11 0x2c0 0x11 0x2d1 0x11 0x2d0>;
		decon_board = <0x65>;
		status = "okay";
		samsung,power-domain = <0x62>;
		lcd_info = <0x64>;
	};

	devfreq_mif@17000010 {
		reg = <0x00 0x17000010 0x00>;
		use_delay_time = "true";
		use_pd_off = "false";
		use_sw_clk = "true";
		use_get_dev = "false";
		compatible = "samsung,exynos-devfreq";
		clock-names = "dvfs_mif\0dvfs_mif_sw";
		devfreq_type = "mif";
		polling_ms = <0x00>;
		clocks = <0x11 0x3e8 0x11 0x3e9>;
		devfreq_domain_name = "dvfs_mif";
		freq_info = <0xa2990 0x65518 0x65518 0x65518 0xa2990 0x65518>;
		use_cl_dvfs = "false";
		delay_time_list = "20";
		use_reg = "true";
		use_tmu = "true";
		boot_qos_timeout = <0x28>;
		gov_name = "interactive";
		reg_name = "BUCK1";
		volt_info = <0x61a8 0x1312d0 0x00 0x13d620>;
	};

	devfreq_int@17000020 {
		reg = <0x00 0x17000020 0x00>;
		use_delay_time = "false";
		use_pd_off = "false";
		use_sw_clk = "false";
		use_get_dev = "false";
		compatible = "samsung,exynos-devfreq";
		clock-names = "dvfs_int";
		devfreq_type = "int";
		polling_ms = <0x00>;
		clocks = <0x11 0x3ea>;
		devfreq_domain_name = "dvfs_int";
		freq_info = <0x72038 0x65518 0x72038 0x65518 0x72038 0x65518>;
		use_cl_dvfs = "false";
		use_reg = "true";
		use_tmu = "true";
		boot_qos_timeout = <0x28>;
		gov_name = "interactive";
		reg_name = "BUCK1";
		volt_info = <0x61a8 0x1312d0 0x00 0x13d620>;
	};

	devfreq_disp@17000030 {
		reg = <0x00 0x17000030 0x00>;
		use_delay_time = "false";
		use_pd_off = "false";
		use_sw_clk = "false";
		use_get_dev = "false";
		compatible = "samsung,exynos-devfreq";
		clock-names = "dvfs_disp";
		devfreq_type = "disp";
		polling_ms = <0x00>;
		clocks = <0x11 0x3ec>;
		devfreq_domain_name = "dvfs_disp";
		freq_info = <0x32c80 0x32c80 0x32c80 0x32c80 0x32c80 0x32c80>;
		use_cl_dvfs = "false";
		use_reg = "true";
		use_tmu = "true";
		boot_qos_timeout = <0x28>;
		gov_name = "interactive";
		reg_name = "BUCK1";
		volt_info = <0x61a8 0x1312d0 0x00 0x13d620>;
	};

	devfreq_cam@17000040 {
		reg = <0x00 0x17000040 0x00>;
		use_delay_time = "false";
		use_pd_off = "true";
		use_sw_clk = "false";
		use_get_dev = "false";
		compatible = "samsung,exynos-devfreq";
		clock-names = "dvfs_cam";
		devfreq_type = "cam";
		polling_ms = <0x00>;
		clocks = <0x11 0x3eb>;
		devfreq_domain_name = "dvfs_cam";
		freq_info = <0x6c660 0x6c660 0x6c660 0x6c660 0x87410 0x6c660>;
		use_cl_dvfs = "false";
		use_reg = "true";
		use_tmu = "true";
		boot_qos_timeout = <0x00>;
		gov_name = "interactive";
		reg_name = "BUCK1";
		volt_info = <0x61a8 0x1312d0 0x00 0x13d620>;
	};

	decon_fb@14830000 {
		disp-dvfs = <0xc65d400>;
		reg = <0x00 0x14830000 0x8000>;
		disp-vclk = <0xbebc200>;
		interrupts = <0x00 0xc9 0x00 0x00 0xca 0x00 0x00 0xcb 0x00 0x00 0x168 0x00>;
		trig_mode = <0x01>;
		vclk-denom = <0x26d>;
		vclk-num = <0x400>;
		compatible = "samsung,exynos5-decon_driver";
		default_win = <0x00>;
		clock-names = "decon_core\0vclk_user\0vclk_leaf";
		max_win = <0x03>;
		mif-vclk = <0xbebc200>;
		clocks = <0x11 0x2bf 0x11 0x2da 0x11 0x2db>;
		ip_ver = <0x04>;
		n_sink_pad = <0x03>;
		dsi_mode = <0x00>;
		ranges;
		#pb-id-cells = <0x00>;
		n_src_pad = <0x01>;
		#address-cells = <0x02>;
		phandle = <0x6d>;
		#size-cells = <0x01>;
		samsung,power-domain = <0x62>;
		linux,phandle = <0x6d>;
		psr_mode = <0x00>;
	};

	decon_board {
		gpio_blic_on = <0x17 0x02 0x01>;
		gpio_panel_enn = <0x18 0x01 0x01>;
		gpio_panel_enp = <0x18 0x00 0x01>;
		gpio_lcd_rst = <0x76 0x00 0x01>;
		phandle = <0x65>;
		linux,phandle = <0x65>;

		dsim_set_panel_power_early {
			type = "regulator,enable\0LCD_1P8\0delay,usleep\01000 2000";
		};

		dsim_set_panel_power_enable {
			type = "gpio,high\0gpio_panel_enp\0delay,usleep\01000 2000\0gpio,high\0gpio_panel_enn\0delay,usleep\010000 11000\0gpio,high\0gpio_blic_on\0delay,usleep\01000 2000";
		};

		dsim_reset_panel {
			type = "gpio,high\0gpio_lcd_rst\0delay,usleep\01000 1100\0gpio,low\0gpio_lcd_rst\0delay,usleep\01000 1100\0gpio,high\0gpio_lcd_rst\0delay,msleep\0130";
		};

		dsim_set_panel_power_disable {
			type = "delay,usleep\05000 6000\0gpio,low\0gpio_panel_enn\0delay,usleep\05000 6000\0gpio,low\0gpio_panel_enp\0delay,usleep\015000 16000\0gpio,low\0gpio_lcd_rst\0delay,usleep\05000 6000\0gpio,low\0gpio_blic_on\0delay,usleep\010000 11000\0regulator,disable\0LCD_1P8";
		};
	};

	dbgdev-pd-mfcmscl {
		compatible = "samsung,exynos-pd-dbg";
		samsung,power-domain = <0x0a>;
	};

	dbgdev-pd-isp {
		compatible = "samsung,exynos-pd-dbg";
		samsung,power-domain = <0x0c>;
	};

	dbgdev-pd-g3d {
		compatible = "samsung,exynos-pd-dbg";
		samsung,power-domain = <0x0d>;
	};

	dbgdev-pd-dispaud {
		compatible = "samsung,exynos-pd-dbg";
		samsung,power-domain = <0x0b>;
	};

	cpus {
		#address-cells = <0x02>;
		#size-cells = <0x00>;

		cpu@3 {
			reg = <0x00 0x03>;
			compatible = "arm,cortex-a53\0arm,armv8";
			enable-method = "psci";
			device_type = "cpu";
			cpu-idle-states = <0x0e>;
		};

		cpu@2 {
			reg = <0x00 0x02>;
			compatible = "arm,cortex-a53\0arm,armv8";
			enable-method = "psci";
			device_type = "cpu";
			cpu-idle-states = <0x0e>;
		};

		cpu@1 {
			reg = <0x00 0x01>;
			compatible = "arm,cortex-a53\0arm,armv8";
			enable-method = "psci";
			device_type = "cpu";
			cpu-idle-states = <0x0e>;
		};

		cpu@0 {
			reg = <0x00 0x00>;
			compatible = "arm,cortex-a53\0arm,armv8";
			enable-method = "psci";
			device_type = "cpu";
			cpu-idle-states = <0x0e>;
		};

		idle-states {
			entry-method = "arm,psci";

			cpu-sleep {
				desc = "cpu sleep";
				compatible = "exynos,idle-state";
				arm,psci-suspend-param = <0x10000>;
				exit-latency-us = <0x5a>;
				status = "okay";
				phandle = <0x0e>;
				entry-latency-us = <0x23>;
				min-residency-us = <0x2ee>;
				linux,phandle = <0x0e>;
			};
		};
	};

	cpufreq {
		cl0_boot_min_qos = <0x1506d0>;
		cl0_regulator = "BUCK1";
		cl0_idx_num = <0x11>;
		compatible = "samsung,exynos-sc-cpufreq";
		cl0_max_support_idx = <0x05>;
		cl0_dvfs_domain_name = "dvfs_cpucl0";
		cl0_en_ema = <0x00>;
		cl0_min_support_idx = <0x0e>;
		cl0_boot_max_qos = <0x1506d0>;
		cl0_boot_lock_time = <0x2625a00>;
	};

	cp_dummy {
		compatible = "samsung,cp_dummy";
		status = "okay";
		phandle = <0x85>;
		linux,phandle = <0x85>;
	};

	coresight@16000000 {
		base = <0x16000000>;
		compatible = "exynos,coresight";
		sjtag-offset = <0x6000>;

		cs_apollo2@600000 {
			device_type = "cs";
			dbg-offset = <0x610000>;
		};

		cs_apollo0@400000 {
			device_type = "cs";
			dbg-offset = <0x410000>;
		};

		cs_apollo3@700000 {
			device_type = "cs";
			dbg-offset = <0x710000>;
		};

		cs_apollo1@500000 {
			device_type = "cs";
			dbg-offset = <0x510000>;
		};
	};

	cmu_fsys@0x13730000 {
		reg = <0x00 0x13730000 0x2000>;
		compatible = "samsung,exynos7570-cmu_fsys\0syscon";
		phandle = <0x66>;
		linux,phandle = <0x66>;
	};

	clock-controller@0x10460000 {
		reg = <0x00 0x10460000 0x1000>;
		#clock-cells = <0x01>;
		compatible = "samsung,exynos7570-clock";
		phandle = <0x11>;
		linux,phandle = <0x11>;
	};

	chosen {
		revision = <0x04>;
		linux,initrd-end = <0x432f6e2e>;
		serial = <0x27670042 0xd99488e4>;
		bootargs = "console=ram loglevel=4 sec_debug.level=0 sec_watchdog.sec_pet=5 DynSysLog=1 androidboot.debug_level=0x4f4c sec_debug.chipidfail_cnt=0 sec_debug.lpitimeout_cnt=0 sec_debug.cache_err_cnt=0 sec_debug.codediff_cnt=0 sec_debug.pcb_offset=7343872 sec_debug.smd_offset=7344896 sec_debug.lpddr4_size=2 sec_debug.sjl=1 androidboot.prototype.param.offset=7345920 ess_setup=0x46600000 tima_log=0x200000@0x52800000 sec_avc_log=0x40000@0x4700a000 sec_tsp_log=0x40000@0x4704c000 sec_debug.base=0x100000@0x4708e000 auto_summary_log=0x10000@0x47190000 s3cfb.bootloaderfb=0x67000000 lcdtype=4940320 androidboot.carrierid.param.offset=7340608 androidboot.carrierid= consoleblank=0 vmalloc=384m sec_debug.reset_reason=7 sec_reset.reset_reason=7 ehci_hcd.park=3 oops=panic pmic_info=19 fg_reset=0 androidboot.emmc_checksum=3 androidboot.sales.param.offset=7340572 sales_code=XEO androidboot.odin_download=1 androidboot.bootloader=J330FXXS4CUD3 androidboot.selinux=enforcing androidboot.security_mode=1526595584 androidboot.ucs_mode=0 androidboot.revision=4 androidboot.hardware=samsungexynos7570 androidboot.warranty_bit=1 androidboot.wb.hs=0500 sec_debug.bin=A androidboot.hmac_mismatch=0 androidboot.sec_atd.tty=/dev/ttySAC2 androidboot.serialno=42006727e48894d9 androidboot.ap_serial=0x05752C74C5C4 snd_soc_core.pmdown_time=1000 androidboot.em.did=05752c74c5c4 androidboot.em.model=SM-J330F androidboot.em.status=0x0 androidboot.verifiedbootstate=orange bcm_setup=0xffffff80f8e00000 reserve-fimc=0 firmware_class.path=/vendor/firmware";
		linux,initrd-start = <0x43000000>;
	};

	chipid@10100000 {
		reg = <0x00 0x10100000 0x100>;
		compatible = "samsung,exynos4210-chipid";
	};

	but_zones {
		#list-but-cells = <0x03>;
		phandle = <0x46>;
		linux,phandle = <0x46>;
	};

	bt_dummy {
		compatible = "samsung,bt_dummy";
		status = "okay";
		phandle = <0x86>;
		linux,phandle = <0x86>;
	};

	battery {
		battery,battery_check_type = <0x05>;
		battery,check_count = <0x00>;
		battery,full_check_type = <0x07>;
		battery,temp_low_recovery_normal = <0x32>;
		battery,polling_time = <0x0a 0x1e 0x1e 0x1e 0xe10>;
		battery,polling_type = <0x01>;
		battery,charging_by_single;
		battery,age_data = <0x00 0x10fe 0x109a 0x109a 0x5d 0xc8 0x10ea 0x1086 0x1086 0x5c 0xfa 0x10d6 0x1072 0x1072 0x5b 0x12c 0x10c2 0x105e 0x105e 0x5a 0x3e8 0x1090 0x102c 0x102c 0x59>;
		battery,temp_highlimit_recovery_lpm = <0x2ee>;
		battery,swelling_low_rechg_voltage = <0xfa0>;
		battery,temp_high_threshold_lpm = <0x1f4>;
		battery,chg_skip_check_capacity = <0x0a>;
		battery,temp_low_threshold_normal = <0x00>;
		battery,full_check_count = <0x01>;
		compatible = "samsung,sec-battery";
		battery,swelling_low_temp_block_1st = <0x96>;
		battery,swelling_low_temp_block_2nd = <0x32>;
		io-channel-names = "adc-temp\0adc-in-bat";
		battery,temp_adc_type = <0x01>;
		battery,recharge_check_count = <0x02>;
		battery,swelling_drop_float_voltage = <0x1036>;
		battery,chg_high_temp_recovery = <0x20d>;
		battery,temp_table_data = <0x384 0x352 0x320 0x2ee 0x2bc 0x28a 0x258 0x226 0x1f4 0x1c2 0x1ae 0x190 0x15e 0x12c 0xfa 0xc8 0x96 0x64 0x32 0x00 0xffffffe2 0xffffffce 0xffffff9c 0xffffff6a 0xffffff38>;
		battery,fast_charging_current = <0x4b0 0x00 0x00 0x4b0 0x1cc 0x4b0 0x3e8 0x1cc 0x4b0 0x00 0x4b0 0x4b0 0x4b0 0x4b0 0x4b0 0x00 0x00 0x190 0x2bc 0x4b0 0x12c 0x3e8 0x4b0 0x00 0x9f6 0x9f6 0x3e8 0x9f6 0x50 0x708 0x3e8 0x578 0x00 0x3e8 0x4b0 0x4b0 0x00>;
		battery,full_check_current_1st = <0xf0 0x00 0x00 0xf0 0xf0 0xf0 0xf0 0xf0 0xf0 0x00 0xf0 0xf0 0xf0 0xf0 0xf0 0x00 0x00 0xf0 0xf0 0xf0 0xf0 0xf0 0xf0 0x00 0xf0 0xf0 0xf0 0xf0 0x00 0xf0 0xf0 0xf0 0x00 0xf0 0xf0 0xf0 0x00>;
		battery,full_check_current_2nd = <0x78 0x00 0x00 0x78 0x78 0x78 0x78 0x78 0x78 0x00 0x78 0x78 0x78 0x78 0x78 0x00 0x00 0x78 0x78 0x78 0x78 0x78 0x78 0x00 0x78 0x78 0x78 0x78 0x00 0x78 0x78 0x78 0x00 0x78 0x78 0x78 0x00>;
		battery,cable_source_type = <0x01>;
		battery,temp_high_recovery_lpm = <0x1c2>;
		battery,inbat_voltage = <0x01>;
		battery,temp_high_recovery_normal = <0x1c2>;
		battery,chg_charging_limit_current_2nd = <0x514>;
		battery,expired_time = <0x41a0>;
		battery,inbat_voltage_table_data = <0x10fe 0x10ea 0x10cc 0x10ae 0x109a 0x1068 0x1054 0x102c 0x1004 0xfd2 0xfaa 0xfa0 0xf8c 0xf6e 0xf5a 0xf46 0xf3c 0xf28 0xf14 0xf00 0xee2 0xed8 0xec4 0xea6 0xe88 0xe60 0xe38 0xe10 0xdfc 0xdde 0xdac 0xd7a>;
		battery,charging_reset_time = <0x00>;
		battery,charger_name = "s2mpu06-charger";
		battery,swelling_high_temp_current = <0x3e8>;
		battery,chg_gpio_full_check = <0x00>;
		battery,inbat_voltage_table_adc = <0xae5 0xadd 0xacc 0xabb 0xab1 0xa92 0xa8a 0xa76 0xa60 0xa43 0xa30 0xa29 0xa18 0xa05 0x9fc 0x9f1 0x9ec 0x9e0 0x9d2 0x9c9 0x9bb 0x9b3 0x9a8 0x995 0x985 0x973 0x95e 0x946 0x93d 0x92c 0x90f 0x8ee>;
		battery,swelling_block_time = <0x258>;
		battery,wpc_high_temp = <0x1a4>;
		battery,wpc_high_temp_recovery = <0x19a>;
		battery,swelling_high_temp_block = <0x19a>;
		battery,check_adc_max = <0x5a0>;
		battery,check_adc_min = <0x00>;
		battery,temp_check_count = <0x01>;
		battery,swelling_high_temp_recov = <0x186>;
		battery,temp_high_threshold_normal = <0x1f4>;
		battery,charging_total_time = <0x5460>;
		battery,fuelgauge_name = "s2mpu06-fuelgauge";
		battery,temp_check_type = <0x02>;
		io-channel-ranges;
		battery,swelling_low_temp_2step_mode = <0x01>;
		battery,temp_highlimit_threshold_normal = <0x320>;
		battery,cable_check_type = <0x04>;
		battery,swelling_high_rechg_voltage = <0xfa0>;
		battery,chg_skip_check_time = <0x258>;
		battery,temp_low_threshold_lpm = <0x00>;
		battery,swelling_low_temp_topoff = <0x8c>;
		battery,ovp_uvlo_check_type = <0x03>;
		battery,temp_highlimit_recovery_normal = <0x2ee>;
		battery,chg_float_voltage = <0x10fe>;
		battery,full_condition_soc = <0x5d>;
		battery,chg_polarity_full_check = <0x01>;
		battery,chg_charging_limit_current = <0x514>;
		battery,swelling_low_temp_recov_1st = <0xc8>;
		battery,swelling_low_temp_recov_2nd = <0x64>;
		battery,recharging_total_time = <0x1518>;
		battery,temp_table_adc = <0x12c 0x162 0x19c 0x1ea 0x235 0x295 0x31b 0x38c 0x423 0x4ba 0x4f6 0x55c 0x622 0x6f4 0x7da 0x8c0 0x9bf 0xaa6 0xb6d 0xc36 0xcaa 0xcfc 0xd8d 0xe07 0xe69>;
		status = "okay";
		battery,wpc_charging_limit_current = <0x1c2>;
		battery,standard_curr = <0x40a>;
		battery,monitor_initial_count = <0x00>;
		battery,chip_vendor = "LSI";
		battery,recharge_condition_soc = <0x62>;
		battery,recharge_condition_type = <0x04>;
		battery,chg_high_temp_1st = <0x212>;
		battery,chg_high_temp_2nd = <0x212>;
		battery,full_condition_vcell = <0x109a>;
		battery,temp_highlimit_threshold_lpm = <0x320>;
		io-channels = <0x45 0x01 0x45 0x05>;
		battery,recharge_condition_vcell = <0x109a>;
		battery,wireless_cc_cv = <0x56>;
		battery,full_condition_type = <0x0f>;
		battery,adc_check_count = <0x05>;
		battery,battery_full_capacity = <0x960>;
		battery,full_check_type_2nd = <0x07>;
		battery,thermal_source = <0x02>;
		battery,swelling_low_temp_current = <0x2d0>;
		battery,recharging_expired_time = <0x1518>;
		battery,technology = <0x02>;
		battery,vendor = "SDI SDI";
		battery,input_current_limit = <0x3e8 0x1cc 0x1cc 0x3e8 0x1cc 0x384 0x3e8 0x1cc 0x3e8 0x00 0x334 0x334 0x334 0x3e8 0x3e8 0x00 0x00 0x190 0x2bc 0x3e8 0x12c 0x3e8 0x3e8 0x00 0x683 0x683 0x3e8 0x683 0x50 0x708 0x683 0x578 0x3e8 0x3e8 0x334 0x334 0x1cc>;
		#io-channel-cells = <0x02>;
		pinctrl-names = "default";
		battery,swelling_high_temp_topoff = <0x8c>;
		battery,temp_low_recovery_lpm = <0x32>;
	};

	arm-pmu {
		interrupts = <0x00 0x32 0x04 0x00 0x33 0x04 0x00 0x34 0x04 0x00 0x35 0x04>;
		compatible = "arm,armv8-pmuv3";
	};

	argos {
		compatible = "samsung,argos";
		#address-cells = <0x01>;

		boot_device@4 {
			net_boost,label = "WIFI";
			net_boost,table = <0x0a 0xfde80 0x00 0x65518 0x00 0x00 0x00 0x3c 0x1506d0 0x00 0xa2990 0x00 0x01 0x01 0x78 0x1506d0 0x00 0xa2990 0x00 0x01 0x01>;
			net_boost,node = "wlan0";
			net_boost,table_size = <0x03>;
		};

		boot_device@3 {
			net_boost,label = "P2P";
			net_boost,table = <0x1e 0x137090 0x00 0x65518 0x00 0x00 0x00 0x32 0x1506d0 0x00 0x65518 0x00 0x00 0x00 0x5a 0x1506d0 0x00 0xa2990 0x00 0x01 0x01>;
			net_boost,node = "p2p-wlan0-0";
			net_boost,table_size = <0x03>;
		};

		boot_device@2 {
			net_boost,label = "USB";
			net_boost,table = <0x01 0x00 0x00 0x00 0x00 0x00 0x01>;
			net_boost,node = "rndis0";
			net_boost,table_size = <0x01>;
		};

		boot_device@1 {
			net_boost,label = "IPC";
			net_boost,table = <0x01 0x00 0x00 0x00 0x00 0x00 0x01 0x14 0xca648 0x00 0x65900 0x186a0 0x00 0x01 0x32 0xfde80 0x00 0xc96a8 0x186a0 0x00 0x01 0x64 0x15d1f0 0x00 0xc96a8 0x186a0 0x00 0x01>;
			net_boost,node = "rmnet0 rmnet1 rmnet2 rmnet3 rmnet4 rmnet5 rmnet6 rmnet7 umts_dm0";
			net_boost,table_size = <0x04>;
		};
	};

	amba {
		compatible = "arm,amba-bus";
		ranges;
		#address-cells = <0x02>;
		#size-cells = <0x01>;
		interrupt-parent = <0x01>;

		pdma0@10490000 {
			reg = <0x00 0x10490000 0x1000>;
			interrupts = <0x00 0x17f 0x00>;
			compatible = "arm,pl330\0arm,primecell";
			clock-names = "apb_pclk";
			clocks = <0x11 0x32>;
			#dma-requests = <0x20>;
			#dma-channels = <0x08>;
			#dma-cells = <0x01>;
			phandle = <0x3e>;
			linux,phandle = <0x3e>;
		};
	};

	aliases {
		mfc0 = "/mfc0@12C30000";
		spi0 = "/spi@100C0000";
		spi1 = "/spi@13900000";
		spi2 = "/spi@13910000";
		spi3 = "/spi@13930000";
		dsim0 = "/dsim@14800000";
		mshc0 = "/dwmmc0@13540000";
		mshc2 = "/dwmmc2@13560000";
		uart1 = "/uart@13800000";
		uart2 = "/uart@13820000";
		uart3 = "/uart@13910000";
		uart4 = "/uart@13930000";
		scaler0 = "/iommu-domain_mfc_mscl/scaler@12C10000";
		decon0 = "/decon_fb@14830000";
		pinctrl0 = "/pinctrl@139F0000";
		pinctrl1 = "/pinctrl@148C0000";
		pinctrl2 = "/pinctrl@139E0000";
		pinctrl3 = "/pinctrl@13750000";
		pinctrl4 = "/pinctrl@10530000";
		pinctrl5 = "/pinctrl@139C0000";
		pinctrl6 = "/pinctrl@139B0000";
		pinctrl7 = "/pinctrl@139D0000";
		tmuctrl0 = "/tmuctrl_CPUCL0@10130000";
		tmuctrl1 = "/tmuctrl_G3D@10130000";
		hsi2c0 = "/hsi2c@13950000";
		hsi2c1 = "/hsi2c@13960000";
		hsi2c2 = "/hsi2c@138A0000";
		hsi2c3 = "/hsi2c@138C0000";
		hsi2c4 = "/hsi2c@138B0000";
		hsi2c5 = "/hsi2c@13910000";
		hsi2c6 = "/hsi2c@13920000";
		hsi2c7 = "/hsi2c@13930000";
		hsi2c8 = "/hsi2c@13940000";
	};

	adc@10550000 {
		reg = <0x00 0x10550000 0x1000>;
		interrupts = <0x00 0x18b 0x00>;
		compatible = "samsung,exynos-adc-v3";
		clock-names = "gate_adcif";
		clocks = <0x11 0x0a>;
		io-channel-ranges;
		phandle = <0x45>;
		#io-channel-cells = <0x01>;
		linux,phandle = <0x45>;
	};

	acpm_ipc@11C00000 {
		reg = <0x00 0x11c00000 0x1000>;
		interrupts = <0x00 0x16 0x00>;
		compatible = "samsung,exynos-acpm-ipc";
		#address-cells = <0x02>;
		#size-cells = <0x01>;

		channels {
			max_buff_size = <0x300>;
			polling = <0x01>;

			framework@0x02047400 {
				buff_size = <0x0c>;
				rx_buff = <0x2047400>;
				tx_buff = <0x2047480>;
				buff_len = <0x08>;
				phandle = <0x83>;
				channel_id = <0x00>;
				direction_buff = <0x19c>;
				linux,phandle = <0x83>;
			};
		};
	};

	acpm@11C88000 {
		reg = <0x00 0x11c88000 0x1000>;
		log_buff_len = <0x17c>;
		compatible = "samsung,exynos-acpm";
		dump_base = <0x2046000>;
		dump_size = <0x3800>;
		logging_period = <0x1f4>;
		debug_logging_level = <0x00>;
		#address-cells = <0x02>;
		log_base = <0x2047700>;
		time_len = <0x20>;
		log_buff_size = <0x10>;
		#size-cells = <0x01>;

		plugins {

			framework {
				id = <0x00>;
				attach = <0x02>;
				acpm-ipc-channel = <0x83>;
			};
		};
	};

	ITM@0 {
		compatible = "samsung,exynos-itm";
	};
};
